VERSION ""

NS_ :

BS_:

BU_: VT OPC
VAL_TABLE_ FMI 21 "Data Drifted Low" 20 "Data Drifted High" 31 "Not available" 19 "Received network data in error" 18 "Below normal (moderately severe)" 17 "Below normal (least severe)" 16 "Above normal (moderately severe)" 15 "Above normal (least severe)" 14 "Special intstructions" 13 "Out of calibration" 12 "Bad intelligent device" 11 "Root cause not known" 10 "Abnormal rate of change" 9 "Abnormal update rate" 8 "Abnormal frequency" 7 "Mechanical system not responding" 6 "Current above normal" 5 "Current below normal" 4 "Voltage below normal" 3 "Voltage above normal" 2 "Data erratic" 1 "Below normal (most severe)" 0 "Above normal (most severe)" ;

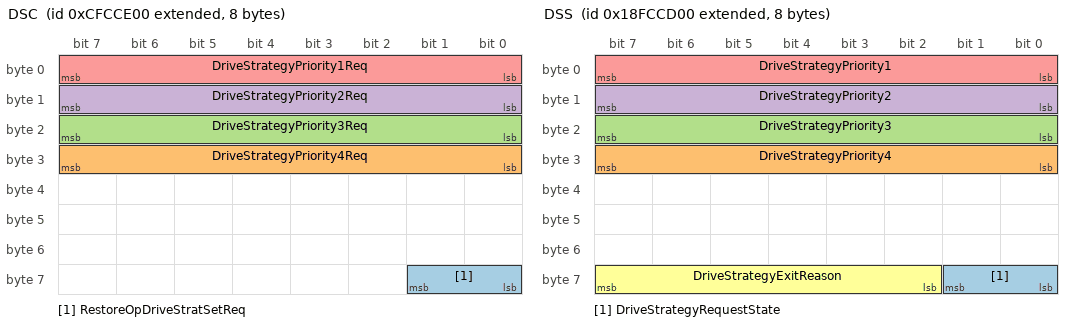
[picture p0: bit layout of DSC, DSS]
BO_ 2365378048 DSC: 8 Vector__XXX
 SG_ RestoreOpDriveStratSetReq : 56|2@1+ (1,0) [0|3] "" Vector__XXX
 SG_ DriveStrategyPriority4Req : 24|8@1+ (1,0) [0|255] "" Vector__XXX
 SG_ DriveStrategyPriority3Req : 16|8@1+ (1,0) [0|255] "" Vector__XXX
 SG_ DriveStrategyPriority2Req : 8|8@1+ (1,0) [0|255] "" Vector__XXX
 SG_ DriveStrategyPriority1Req : 0|8@1+ (1,0) [0|255] "" Vector__XXX

BO_ 2566704384 DSS: 8 Vector__XXX
 SG_ DriveStrategyRequestState : 56|2@1+ (1,0) [0|3] "" Vector__XXX
 SG_ DriveStrategyPriority4 : 24|8@1+ (1,0) [0|255] "" Vector__XXX
 SG_ DriveStrategyPriority3 : 16|8@1+ (1,0) [0|255] "" Vector__XXX
 SG_ DriveStrategyPriority2 : 8|8@1+ (1,0) [0|255] "" Vector__XXX
 SG_ DriveStrategyPriority1 : 0|8@1+ (1,0) [0|255] "" Vector__XXX
 SG_ DriveStrategyExitReason : 58|6@1+ (1,0) [0|63] "" Vector__XXX

BO_ 2566843646 VI: 8 Vector__XXX
 SG_ VehicleIdentificationNumber : 0|8@1+ (1,0) [0|255] "per byte" Vector__XXX

BO_ 2559835902 NM: 8 Vector__XXX
 SG_ NameChecksum m0 : 0|8@1+ (1,0) [0|0] "" Vector__XXX
 SG_ ErrorCode m4 : 0|8@1+ (1,0) [0|0] "" Vector__XXX
 SG_ CommandArbitraryAddressCapable m0 : 63|1@1+ (1,0) [0|1] "" Vector__XXX
 SG_ CommandVehicleSystemInstance m0 : 56|4@1+ (1,0) [0|15] "" Vector__XXX
 SG_ CommandIndustryGroup m0 : 60|3@1+ (1,0) [0|7] "" Vector__XXX
 SG_ CommandVehicleSystem m0 : 49|7@1+ (1,0) [0|127] "" Vector__XXX
 SG_ CommandFunction m0 : 40|8@1+ (1,0) [0|255] "" Vector__XXX
 SG_ CommandFunctionInstance m0 : 35|5@1+ (1,0) [0|31] "" Vector__XXX
 SG_ CommandECUInstance m0 : 32|3@1+ (1,0) [0|7] "" Vector__XXX
 SG_ CommandManufacturerCode m0 : 21|11@1+ (1,0) [0|2047] "" Vector__XXX
 SG_ NMControlModeIndicator M : 16|4@1+ (1,0) [0|15] "" Vector__XXX
 SG_ ArbitraryAddressCapableQualifier m0 : 15|1@1+ (1,0) [0|1] "" Vector__XXX
 SG_ IndustryGroupQualifierFlag m0 : 14|1@1+ (1,0) [0|1] "" Vector__XXX
 SG_ VehicleSystemInstanceQualifierFl m0 : 13|1@1+ (1,0) [0|1] "" Vector__XXX
 SG_ VehicleSystemQualifierFlag m0 : 12|1@1+ (1,0) [0|1] "" Vector__XXX
 SG_ FunctionQualifierFlag m0 : 11|1@1+ (1,0) [0|1] "" Vector__XXX
 SG_ FunctionInstanceQualifierFlag m0 : 10|1@1+ (1,0) [0|1] "" Vector__XXX
 SG_ ECUInstanceQualifierFlag m0 : 9|1@1+ (1,0) [0|1] "" Vector__XXX
 SG_ ManufacturerCodeQualifierFlag m0 : 8|1@1+ (1,0) [0|1] "" Vector__XXX

BO_ 2358116094 SCCCM: 8 Vector__XXX
 SG_ MessageCode M : 0|8@1+ (1,0) [0|255] "" Vector__XXX
 SG_ DeleteCommandType m5 : 8|8@1+ (1,0) [0|1] "" Vector__XXX
 SG_ AddressSCCWSM m4 : 8|8@1+ (1,0) [0|253] "" Vector__XXX
 SG_ MemoryRequired m145 : 8|32@1+ (1,0) [0|4294967295] "bytes" Vector__XXX
 SG_ FunctionID m50 : 8|8@1+ (1,0) [0|255] "" Vector__XXX
 SG_ SCCState m150 : 8|8@1+ (1,0) [0|2] "" Vector__XXX
 SG_ RecordedFunctionID m52 : 8|8@1+ (1,0) [0|255] "" Vector__XXX
 SG_ NumberOfFaultyFunctions m53M : 8|8@1+ (1,0) [0|255] "" Vector__XXX
 SG_ SequenceNumber m150 : 16|8@1+ (1,0) [0|255] "" Vector__XXX
 SG_ StateID m50 : 16|6@1+ (1,0) [0|63] "" Vector__XXX
 SG_ IDOfFaultyClientFunction1 m1 : 16|8@1+ (1,0) [0|255] "" Vector__XXX
 SG_ NewStateID m52 : 16|6@1+ (1,0) [0|63] "" Vector__XXX
 SG_ NewFunctionExecutionState m52 : 22|2@1+ (1,0) [0|3] "" Vector__XXX
 SG_ FunctionExecutionState m50M : 22|2@1+ (1,0) [0|3] "" Vector__XXX
 SG_ SequenceState m150 : 24|8@1+ (1,0) [0|255] "" Vector__XXX
 SG_ ClientAbortError m49 : 24|8@1+ (1,0) [0|255] "" Vector__XXX
 SG_ ClientFunctionErrorStatuts1 m1 : 24|4@1+ (1,0) [0|15] "" Vector__XXX
 SG_ ClientExecutionError m52 : 24|8@1+ (1,0) [0|255] "" Vector__XXX
 SG_ TAN m50 : 24|8@1+ (1,0) [0|255] "" Vector__XXX
 SG_ OperatorConfirmationRequired1 m1 : 31|1@1+ (1,0) [0|1] "" Vector__XXX
 SG_ ClientFunctonErrorState m150 : 32|8@1+ (1,0) [0|255] "" Vector__XXX
 SG_ IDOfFaultyClientFunction2 m2 : 32|8@1+ (1,0) [0|255] "" Vector__XXX
 SG_ FunctionValue m0 : 32|32@1+ (1,0) [0|4294967295] "" Vector__XXX
 SG_ ReceivedTAN m52 : 32|8@1+ (1,0) [0|255] "" Vector__XXX
 SG_ ClientFunctionErrorStatuts2 m2 : 40|4@1+ (1,0) [0|15] "" Vector__XXX
 SG_ OperatorConfirmationRequired2 m2 : 47|1@1+ (1,0) [0|1] "" Vector__XXX
 SG_ IDOfFaultyClientFunction3 m3 : 48|8@1+ (1,0) [0|255] "" Vector__XXX
 SG_ ClientFunctionErrorStatuts3 m3 : 56|4@1+ (1,0) [0|15] "" Vector__XXX
 SG_ OperatorConfirmationRequired3 m3 : 63|1@1+ (1,0) [0|1] "" Vector__XXX

BO_ 2358181630 SCMCC: 8 Vector__XXX
 SG_ MessageCode M : 0|8@1+ (1,0) [0|255] "" Vector__XXX
 SG_ LoadResponseError m7 : 8|8@1+ (1,0) [0|255] "" Vector__XXX
 SG_ StoreCommandError m6 : 8|8@1+ (1,0) [0|255] "" Vector__XXX
 SG_ DeleteCommandResponseError m5 : 8|8@1+ (1,0) [0|255] "" Vector__XXX
 SG_ CommandedSCCState m48 : 8|8@1+ (1,0) [0|1] "" Vector__XXX
 SG_ SCVersion m144 : 8|8@1+ (1,0) [0|255] "" Vector__XXX
 SG_ FunctionID m50 : 8|8@1+ (1,0) [0|255] "" Vector__XXX
 SG_ SCMState m149 : 8|8@1+ (1,0) [0|2] "" Vector__XXX
 SG_ ActivationResponseError m4 : 8|8@1+ (1,0) [0|255] "" Vector__XXX
 SG_ TransferResponseError m3 : 8|8@1+ (1,0) [0|255] "" Vector__XXX
 SG_ ConfigLabelResponseError m2M : 8|8@1+ (1,0) [0|255] "" Vector__XXX
 SG_ VersionResponseError m1M : 8|8@1+ (1,0) [0|255] "" Vector__XXX
 SG_ MemoryStatus m145 : 8|8@1+ (1,0) [0|1] "" Vector__XXX
 SG_ RecordedFunctionID m51 : 8|8@1+ (1,0) [0|255] "" Vector__XXX
 SG_ ObjectIdOfFirstFaultyObject m4 : 16|16@1+ (1,0) [0|65535] "" Vector__XXX
 SG_ SequenceNumber m149 : 16|8@1+ (1,0) [0|255] "" Vector__XXX
 SG_ RecordedStateID m51 : 16|6@1+ (1,0) [0|63] "" Vector__XXX
 SG_ GraphicsWidth m144 : 16|8@1+ (1,0) [32|255] "" Vector__XXX
 SG_ ActualVersionLabel m0 : 16|8@1+ (1,0) [0|255] "" Vector__XXX
 SG_ ActualConfigurationLabel m0 : 16|8@1+ (1,0) [0|255] "" Vector__XXX
 SG_ StateID m50 : 16|6@1+ (1,0) [0|63] "" Vector__XXX
 SG_ FunctionExecutionStateAck m52 : 22|2@1+ (1,0) [0|3] "" Vector__XXX
 SG_ FunctionExecutionState m50 : 22|2@1+ (1,0) [0|3] "" Vector__XXX
 SG_ GraphicsHeight m144 : 24|8@1+ (1,0) [32|255] "" Vector__XXX
 SG_ ReasonIndicator m48 : 24|8@1+ (1,0) [0|255] "" Vector__XXX
 SG_ SequenceState m149 : 24|8@1+ (1,0) [0|255] "" Vector__XXX
 SG_ TAN m51 : 24|8@1+ (1,0) [0|255] "" Vector__XXX
 SG_ ExecutionIndicationResponseError m50 : 24|8@1+ (1,0) [0|255] "" Vector__XXX
 SG_ BusyFlagMemoryAccess m149 : 32|1@1+ (1,0) [0|1] "" Vector__XXX
 SG_ RecordedFunctionValue m51 : 32|32@1+ (1,0) [0|4294967295] "" Vector__XXX
 SG_ ReceivedTAN m50 : 32|8@1+ (1,0) [0|255] "" Vector__XXX
 SG_ BusyFlagParsing m149 : 33|1@1+ (1,0) [0|1] "" Vector__XXX
 SG_ MaxDesignatorStringLength m144 : 32|16@1+ (1,0) [0|65535] "" Vector__XXX

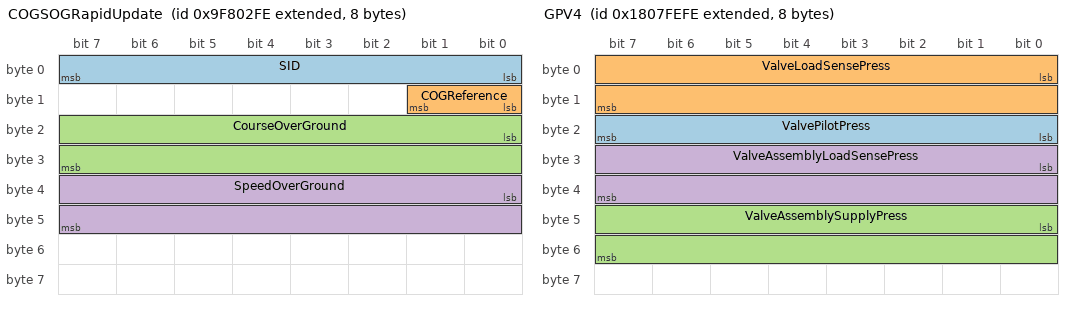
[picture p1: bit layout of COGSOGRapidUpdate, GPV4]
BO_ 2314732286 COGSOGRapidUpdate: 8 Vector__XXX
 SG_ SID : 0|8@1+ (1,0) [0|252] "" Vector__XXX
 SG_ COGReference : 8|2@1+ (1,0) [0|3] "" Vector__XXX
 SG_ CourseOverGround : 16|16@1+ (0.0001,0) [0|6.28318] "rad" Vector__XXX
 SG_ SpeedOverGround : 32|16@1+ (0.01,0) [0|655.32] "m/s" Vector__XXX

BO_ 2365391360 AISO: 8 Vector__XXX
 SG_ StopAllImplementOperations : 56|2@1- (1,0) [0|3] "" Vector__XXX

BO_ 2365391616 IOS: 8 Vector__XXX
 SG_ ImplementOperatingStateCmd : 56|2@1+ (1,0) [0|3] "" Vector__XXX

BO_ 2566835454 DM3: 0 Vector__XXX

BO_ 2364547838 MSS: 9 Vector__XXX
 SG_ MachineSelectedSpeed : 0|16@1+ (0.001,0) [0|65.535] "m/s" Vector__XXX
 SG_ MachineSelectedDistance : 16|32@1+ (0.001,0) [0|4211081.215] "m" Vector__XXX
 SG_ MachineSelectedDirection : 56|2@1+ (1,0) [0|3] "" Vector__XXX
 SG_ MachineSelectedSpeedSource : 58|3@1+ (1,0) [0|7] "" Vector__XXX
 SG_ MachineSelectedSpeedLimitStatus : 61|3@1+ (1,0) [0|7] "" Vector__XXX

BO_ 2550660862 GPV4: 8 Vector__XXX
 SG_ ValvePilotPress : 16|8@1+ (16,0) [0|4000] "kPa" Vector__XXX
 SG_ ValveLoadSensePress : 0|16@1+ (5,0) [0|321275] "kPa" Vector__XXX
 SG_ ValveAssemblySupplyPress : 40|16@1+ (5,0) [0|321275] "kPa" Vector__XXX
 SG_ ValveAssemblyLoadSensePress : 24|16@1+ (5,0) [0|321275] "kPa" Vector__XXX

BO_ 2566730494 DP: 8 Vector__XXX
 SG_ DiagnosticOptions m23 : 40|8@1+ (1,0) [0|255] "" Vector__XXX
 SG_ StopAllImplementOperationsOption m21 : 40|8@1+ (1,0) [0|0] "" Vector__XXX
 SG_ SequenceControlFuncOptions m19 : 40|8@1+ (1,0) [0|255] "" Vector__XXX
 SG_ AdvanceTECU_MotionInitiationOpti m15 : 46|1@1+ (1,0) [0|1] "" Vector__XXX
 SG_ AdvanceTECU_PowertrainOption m15 : 45|1@1+ (1,0) [0|1] "" Vector__XXX
 SG_ AdvanceTECU_GuidanceOption m15 : 44|1@1+ (1,0) [0|1] "" Vector__XXX
 SG_ AdvanceTECU_FrontHitchOption m15 : 43|1@1+ (1,0) [0|1] "" Vector__XXX
 SG_ AdvanceTECU_NavigationOption m15 : 42|1@1+ (1,0) [0|1] "" Vector__XXX
 SG_ AdvanceTECU_FullLightingMsgSet m15 : 41|1@1+ (1,0) [0|1] "" Vector__XXX
 SG_ AdvanceTECU_Class3NoOptions m15 : 40|1@1+ (1,0) [0|1] "" Vector__XXX
 SG_ BasicTECU_GuidanceOption m13 : 45|1@1+ (1,0) [0|1] "" Vector__XXX
 SG_ BasicTECU_FrontHitchOption m13 : 44|1@1+ (1,0) [0|1] "" Vector__XXX
 SG_ BasicTECU_NavigationOption m13 : 43|1@1+ (1,0) [0|1] "" Vector__XXX
 SG_ BasicTECU_ClassRequiredLighting m13 : 42|1@1+ (1,0) [0|1] "" Vector__XXX
 SG_ BasicTECU_Class2NoOptions m13 : 41|1@1+ (1,0) [0|1] "" Vector__XXX
 SG_ BasicTECU_Class1NoOptions m13 : 40|1@1+ (1,0) [0|1] "" Vector__XXX
 SG_ TCSectionNumberOfSections m11 : 48|8@1+ (1,0) [0|250] "" Vector__XXX
 SG_ TCSectionNumberOfBooms m11 : 40|8@1+ (1,0) [0|250] "" Vector__XXX
 SG_ TCGeoFuncOptions m9 : 48|8@1+ (1,0) [0|0] "" Vector__XXX
 SG_ TCGeoSupportedChannels m9 : 40|8@1+ (1,0) [0|250] "" Vector__XXX
 SG_ TCBasicFuncOptions m7 : 40|8@1+ (1,0) [0|255] "" Vector__XXX
 SG_ AuxType2_SupportFunc14 m5 : 54|1@1+ (1,0) [0|1] "" Vector__XXX
 SG_ AuxType2_SupportFunc13 m5 : 53|1@1+ (1,0) [0|1] "" Vector__XXX
 SG_ AuxType2_SupportFunc12 m5 : 52|1@1+ (1,0) [0|1] "" Vector__XXX
 SG_ AuxType2_SupportFunc11 m5 : 51|1@1+ (1,0) [0|1] "" Vector__XXX
 SG_ AuxType2_SupportFunc10 m5 : 50|1@1+ (1,0) [0|1] "" Vector__XXX
 SG_ AuxType2_SupportFunc09 m5 : 49|1@1+ (1,0) [0|1] "" Vector__XXX
 SG_ AuxType2_SupportFunc08 m5 : 48|1@1+ (1,0) [0|1] "" Vector__XXX
 SG_ AuxType2_SupportFunc07 m5 : 47|1@1+ (1,0) [0|1] "" Vector__XXX
 SG_ AuxType2_SupportFunc06 m5 : 46|1@1+ (1,0) [0|1] "" Vector__XXX
 SG_ AuxType2_SupportFunc05 m5 : 45|1@1+ (1,0) [0|1] "" Vector__XXX
 SG_ AuxType2_SupportFunc04 m5 : 44|1@1+ (1,0) [0|1] "" Vector__XXX
 SG_ AuxType2_SupportFunc03 m5 : 43|1@1+ (1,0) [0|1] "" Vector__XXX
 SG_ AuxType2_SupportFunc02 m5 : 42|1@1+ (1,0) [0|1] "" Vector__XXX
 SG_ AuxType2_SupportFunc01 m5 : 41|1@1+ (1,0) [0|1] "" Vector__XXX
 SG_ AuxType2_SupportFunc00 m5 : 40|1@1+ (1,0) [0|1] "" Vector__XXX
 SG_ AuxType1_SupportFunc2 m3 : 42|1@1+ (1,0) [0|1] "" Vector__XXX
 SG_ AuxType1_SupportFunc1 m3 : 41|1@1+ (1,0) [0|1] "" Vector__XXX
 SG_ AuxType1_SupportFunc0 m3 : 40|1@1+ (1,0) [0|1] "" Vector__XXX
 SG_ VTFuncOptions m1 : 40|8@1+ (1,0) [0|250] "" Vector__XXX
 SG_ NumOfFirstListedFuncOptionBytes : 32|8@1+ (1,0) [0|2] "" Vector__XXX
 SG_ FirstListedFuncGen : 24|8@1+ (1,0) [0|255] "" Vector__XXX
 SG_ FirstListedFuncCharacteristic M : 16|8@1+ (1,0) [0|255] "" Vector__XXX
 SG_ NumOfReportedFuncCharacteristics : 8|8@1+ (1,0) [0|255] "" Vector__XXX
 SG_ J1939_73 : 0|1@1+ (1,0) [0|1] "" Vector__XXX
 SG_ ISO14230 : 1|1@1+ (1,0) [0|1] "" Vector__XXX
 SG_ ISO15765_3 : 2|1@1+ (1,0) [0|1] "" Vector__XXX
 SG_ ISO11783Level2 : 3|1@1+ (1,0) [0|1] "" Vector__XXX

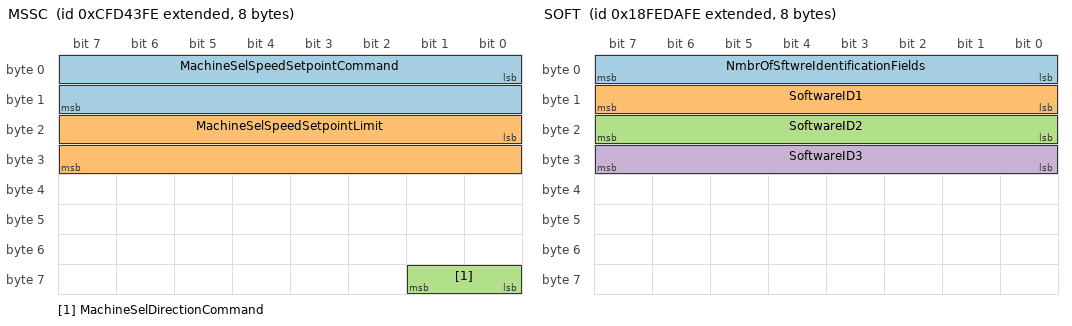
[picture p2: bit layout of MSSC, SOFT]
BO_ 2365408254 MSSC: 8 Vector__XXX
 SG_ MachineSelSpeedSetpointCommand : 0|16@1+ (0.001,0) [0|64255] "m/s" Vector__XXX
 SG_ MachineSelSpeedSetpointLimit : 16|16@1+ (0.001,0) [0|64255] "m/s" Vector__XXX
 SG_ MachineSelDirectionCommand : 56|2@1+ (1,0) [0|3] "" Vector__XXX

BO_ 2566734590 ICC: 8 Vector__XXX
 SG_ CertTypeTCSectionControlWSMember : 41|1@1+ (1,0) [0|1] "" Vector__XXX
 SG_ CertTypeTCSectionControl : 42|1@1+ (1,0) [0|1] "" Vector__XXX
 SG_ CertTypeSeqControlMaster : 44|1@1+ (1,0) [0|1] "" Vector__XXX
 SG_ CertTypeSecControlClient : 43|1@1+ (1,0) [0|1] "" Vector__XXX
 SG_ CertTypeFileClient : 45|1@1+ (1,0) [0|1] "" Vector__XXX
 SG_ CertTypeDataLoggerWSMember : 46|1@1+ (1,0) [0|1] "" Vector__XXX
 SG_ CertTypeDataLoggerWSMaster : 47|1@1+ (1,0) [0|1] "" Vector__XXX
 SG_ CertTypeDataLogger : 32|1@1+ (1,0) [0|1] "" Vector__XXX
 SG_ CertTypeAuxControlInUnit : 34|1@1+ (1,0) [0|1] "" Vector__XXX
 SG_ CertTypeAuxControlFunc : 33|1@1+ (1,0) [0|1] "" Vector__XXX
 SG_ CertificationYear : 0|6@1+ (1,2000) [2000|2061] "year" Vector__XXX
 SG_ CertificateRevision : 6|2@1+ (1,0) [0|3] "" Vector__XXX
 SG_ CertificateLaboratoryType : 9|2@1+ (1,0) [0|3] "" Vector__XXX
 SG_ CertificationLaboratoryID : 13|11@1+ (1,0) [0|2047] "" Vector__XXX
 SG_ CertTypeVTWorkingSetMember : 24|1@1+ (1,0) [0|1] "" Vector__XXX
 SG_ CertTypeVTWorkingSetMaster : 25|1@1+ (1,0) [0|1] "" Vector__XXX
 SG_ CertTypeVirtualTerminal : 26|1@1+ (1,0) [0|1] "" Vector__XXX
 SG_ CertTypeClass3ECU : 27|1@1+ (1,0) [0|1] "" Vector__XXX
 SG_ CertTypeTECUClass3 : 28|1@1+ (1,0) [0|1] "" Vector__XXX
 SG_ CertTypeTECUClass2 : 29|1@1+ (1,0) [0|1] "" Vector__XXX
 SG_ CertTypeTECUClass1 : 30|1@1+ (1,0) [0|1] "" Vector__XXX
 SG_ CertTypeMinimumECU : 31|1@1+ (1,0) [0|1] "" Vector__XXX
 SG_ CertTypeGPSReceiver : 35|1@1+ (1,0) [0|1] "" Vector__XXX
 SG_ CertTypeFileServer : 36|1@1+ (1,0) [0|1] "" Vector__XXX
 SG_ CertTypeTCWorkingSetMember : 37|1@1+ (1,0) [0|1] "" Vector__XXX
 SG_ CertTypeTCWorkingSetMaster : 38|1@1+ (1,0) [0|1] "" Vector__XXX
 SG_ CertTypeTaskController : 39|1@1+ (1,0) [0|1] "" Vector__XXX
 SG_ CertificationReferenceNumber : 48|16@1+ (1,0) [0|65535] "" Vector__XXX

BO_ 2566835198 DM2: 22 Vector__XXX
 SG_ DTC1 : 16|32@1+ (1,0) [0|4294967295] "" Vector__XXX
 SG_ DTC2 : 48|32@1+ (1,0) [0|4294967295] "" Vector__XXX
 SG_ DTC3 : 80|32@1+ (1,0) [0|4294967295] "" Vector__XXX
 SG_ DTC4 : 112|32@1+ (1,0) [0|4294967295] "" Vector__XXX
 SG_ DTC5 : 144|32@1+ (1,0) [0|4294967295] "" Vector__XXX

BO_ 2566834942 DM1: 22 Vector__XXX
 SG_ DTC1 : 16|32@1+ (1,0) [0|4294967295] "" Vector__XXX
 SG_ DTC2 : 48|32@1+ (1,0) [0|4294967295] "" Vector__XXX
 SG_ DTC3 : 80|32@1+ (1,0) [0|4294967295] "" Vector__XXX
 SG_ DTC4 : 112|32@1+ (1,0) [0|4294967295] "" Vector__XXX
 SG_ DTC5 : 144|32@1+ (1,0) [0|4294967295] "" Vector__XXX

BO_ 2566839038 SOFT: 8 Vector__XXX
 SG_ NmbrOfSftwreIdentificationFields : 0|8@1+ (1,0) [0|250] "steps" Vector__XXX
 SG_ SoftwareID1 : 8|8@1+ (1,0) [0|255] "" Vector__XXX
 SG_ SoftwareID2 : 16|8@1+ (1,0) [0|255] "" Vector__XXX
 SG_ SoftwareID3 : 24|8@1+ (1,0) [0|255] "" Vector__XXX

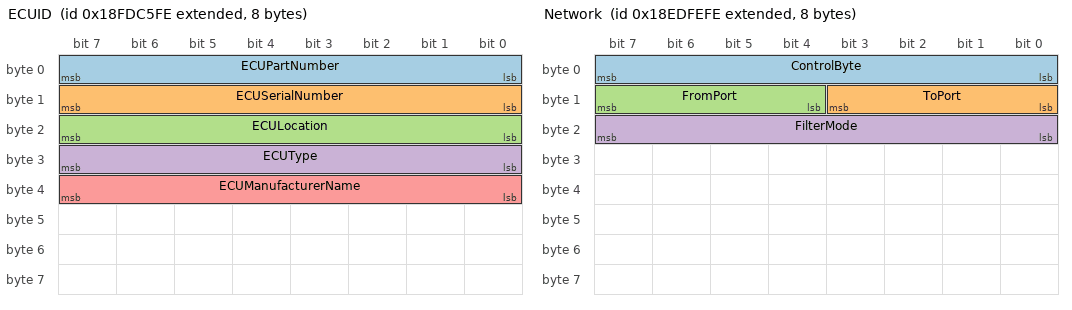
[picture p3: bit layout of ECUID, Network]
BO_ 2566768126 ECUID: 8 Vector__XXX
 SG_ ECUPartNumber : 0|8@1+ (1,0) [0|255] "" Vector__XXX
 SG_ ECUSerialNumber : 8|8@1+ (1,0) [0|255] "" Vector__XXX
 SG_ ECULocation : 16|8@1+ (1,0) [0|255] "" Vector__XXX
 SG_ ECUType : 24|8@1+ (1,0) [0|255] "" Vector__XXX
 SG_ ECUManufacturerName : 32|8@1+ (1,0) [0|255] "" Vector__XXX

BO_ 2566838526 CA: 9 Vector__XXX
 SG_ IdentityNumber : 0|21@1+ (1,0) [0|2097152] "" Vector__XXX
 SG_ ManufacturerCode : 21|11@1+ (1,0) [0|2047] "" Vector__XXX
 SG_ ECUInstance : 32|3@1+ (1,0) [0|7] "" Vector__XXX
 SG_ FunctionInstance : 35|5@1+ (1,0) [0|31] "" Vector__XXX
 SG_ Function : 40|8@1+ (1,0) [0|255] "" Vector__XXX
 SG_ VehicleSystem m0 : 49|7@1+ (1,0) [0|127] "" Vector__XXX
 SG_ VehicleSystem5 m5 : 49|7@1+ (1,0) [0|127] "" Vector__XXX
 SG_ VehicleSystem4 m4 : 49|7@1+ (1,0) [0|127] "" Vector__XXX
 SG_ VehicleSystem3 m3 : 49|7@1+ (1,0) [0|127] "" Vector__XXX
 SG_ VehicleSystem2 m2 : 49|7@1+ (1,0) [0|127] "" Vector__XXX
 SG_ VehicleSystem1 m1 : 49|7@1+ (1,0) [0|127] "" Vector__XXX
 SG_ VehicleSystemInstance : 56|4@1+ (1,0) [0|15] "" Vector__XXX
 SG_ IndustryGroup M : 60|3@1+ (1,0) [0|7] "" Vector__XXX
 SG_ ArbitraryAddressCapable : 63|1@1+ (1,0) [0|1] "" Vector__XXX
 SG_ AddressAssignment : 64|8@1+ (1,0) [0|255] "" Vector__XXX

BO_ 2565799678 ACL: 8 OPC
 SG_ IdentityNumber : 0|21@1+ (1,0) [0|2097152] "" Vector__XXX
 SG_ ManufacturerCode : 21|11@1+ (1,0) [0|2047] "" Vector__XXX
 SG_ ECUInstance : 32|3@1+ (1,0) [0|7] "" Vector__XXX
 SG_ FunctionInstance : 35|5@1+ (1,0) [0|31] "" Vector__XXX
 SG_ Function : 40|8@1+ (1,0) [0|255] "" Vector__XXX
 SG_ VehicleSystem1 m1 : 49|7@1+ (1,0) [0|127] "" Vector__XXX
 SG_ VehicleSystem2 m2 : 49|7@1+ (1,0) [0|127] "" Vector__XXX
 SG_ VehicleSystem3 m3 : 49|7@1+ (1,0) [0|127] "" Vector__XXX
 SG_ VehicleSystem4 m4 : 49|7@1+ (1,0) [0|127] "" Vector__XXX
 SG_ VehicleSystem5 m5 : 49|7@1+ (1,0) [0|127] "" Vector__XXX
 SG_ VehicleSystem m0 : 49|7@1+ (1,0) [0|127] "" Vector__XXX
 SG_ VehicleSystemInstance : 56|4@1+ (1,0) [0|15] "" Vector__XXX
 SG_ IndustryGroup M : 60|3@1+ (1,0) [0|7] "" Vector__XXX
 SG_ ArbitraryAddressCapable : 63|1@1+ (1,0) [0|1] "" Vector__XXX
 SG_ IdentityNumber : 0|21@1+ (1,0) [0|2097152] "" Vector__XXX
 SG_ ManufacturerCode : 21|11@1+ (1,0) [0|2047] "" Vector__XXX
 SG_ ECUInstance : 32|3@1+ (1,0) [0|7] "" Vector__XXX
 SG_ FunctionInstance : 35|5@1+ (1,0) [0|31] "" Vector__XXX
 SG_ Function : 40|8@1+ (1,0) [0|255] "" Vector__XXX
 SG_ VehicleSystem1 m1 : 49|7@1+ (1,0) [0|127] "" Vector__XXX
 SG_ VehicleSystem2 m2 : 49|7@1+ (1,0) [0|127] "" Vector__XXX
 SG_ VehicleSystem3 m3 : 49|7@1+ (1,0) [0|127] "" Vector__XXX
 SG_ VehicleSystem4 m4 : 49|7@1+ (1,0) [0|127] "" Vector__XXX
 SG_ VehicleSystem5 m5 : 49|7@1+ (1,0) [0|127] "" Vector__XXX
 SG_ VehicleSystem m0 : 49|7@1+ (1,0) [0|127] "" Vector__XXX
 SG_ VehicleSystemInstance : 56|4@1+ (1,0) [0|15] "" Vector__XXX
 SG_ IndustryGroup M : 60|3@1+ (1,0) [0|7] "" Vector__XXX
 SG_ ArbitraryAddressCapable : 63|1@1+ (1,0) [0|1] "" Vector__XXX

BO_ 2565734142 Network: 8 Vector__XXX
 SG_ ControlByte : 0|8@1+ (1,0) [0|255] "" Vector__XXX
 SG_ ToPort : 8|4@1+ (1,0) [0|15] "" Vector__XXX
 SG_ FromPort : 12|4@1+ (1,0) [0|15] "" Vector__XXX
 SG_ FilterMode : 16|8@1+ (1,0) [0|255] "" Vector__XXX

CM_ BU_ VT "Virtual Terminal";
CM_ BU_ OPC "Object Pool Checker";
CM_ SG_ 2365378048 RestoreOpDriveStratSetReq "This parameter requests the drive strategy subsystem to restore the settings for drive strategy to the state 
before automation was ended. ";
CM_ SG_ 2365378048 DriveStrategyPriority4Req "This parameter used to request an alteration to the tractor drive strategy priority structure, which determines 
the  balance  between  fuel  economy/consumption  and  the  torque  reserve  of  the  engine - the lowest priority request.  ";
CM_ SG_ 2365378048 DriveStrategyPriority3Req "This parameter used to request an alteration to the tractor drive strategy priority structure, which determines 
the  balance  between  fuel  economy/consumption  and  the  torque  reserve  of  the  engine - the third to highest priority request.";
CM_ SG_ 2365378048 DriveStrategyPriority2Req "This parameter used to request an alteration to the tractor drive strategy priority structure, which determines 
the  balance  between  fuel  economy/consumption  and  the  torque  reserve  of  the  engine - the second to highest priority request.";
CM_ SG_ 2365378048 DriveStrategyPriority1Req "This parameter used to request an alteration to the tractor drive strategy priority structure, which determines 
the  balance  between  fuel  economy/consumption  and  the  torque  reserve  of  the  engine - the highest priority request.";
CM_ BO_ 2566704384 "Message sent from the tractor to the implement to indicate the current status, of the drive strategy priority 
structure, which indicates the priority of the multiple powertrain functions. ";
CM_ SG_ 2566704384 DriveStrategyRequestState "This  parmeter  reports  the  tractor's  state  associated  with  Drive  Strategy  requests  that  are 
transient/temporary/one-shot.";
CM_ SG_ 2566704384 DriveStrategyPriority4 "This parameter indicates the current Tractor drive strategy priority structure, which determines the balance 
between  fuel  economy/consumption  and  the  torque  reserve  of  the  engine.  This  parameter  indicates  the 
lowest priority. ";
CM_ SG_ 2566704384 DriveStrategyPriority3 "This parameter indicates the current Tractor drive strategy priority structure, which determines the balance 
between  fuel  economy/consumption  and  the  torque  reserve  of  the  engine.  This  parameter  indicates 
 the third to highest priority. ";
CM_ SG_ 2566704384 DriveStrategyPriority2 "This parameter indicates the current Tractor drive strategy priority structure, which determines the balance 
between  fuel  economy/consumption  and  the  torque  reserve  of  the  engine.  This  parameter  indicates 
 the second to highest priority. ";
CM_ SG_ 2566704384 DriveStrategyPriority1 "This parameter indicates the current Tractor drive strategy priority structure, which determines the balance 
between  fuel  economy/consumption  and  the  torque  reserve  of  the  engine.  This  parameter  indicates  the 
highest priority. ";
CM_ SG_ 2566704384 DriveStrategyExitReason "Parameter used to indicate why the drive strategy subsystem cannot currently accept remote commands or 
has most recently stopped accepting remote commands.";
CM_ BO_ 2566843646 "Byte: 1-n Vehicle Identification Number 
Delimiter (ASCII “*”)";
CM_ SG_ 2566843646 VehicleIdentificationNumber "Vehicle Identification Number (VIN) as assigned by the vehicle manufacturer.";
CM_ BO_ 2358116094 "Sequence Control Client to Sequence Control Master";
CM_ SG_ 2358116094 AddressSCCWSM "Source address of SCC's working set master";
CM_ SG_ 2358116094 MemoryRequired "Volatile memory required, number of bytes of the SCD to upload";
CM_ SG_ 2358116094 ClientAbortError "Error code of a SCClientAbort";
CM_ BO_ 2358181630 "Sequence Control Master to Sequence Control Client";
CM_ SG_ 2358181630 MessageCode "Message code of the SCMCC message";
CM_ SG_ 2358181630 SCVersion "Version of supported SC standard";
CM_ SG_ 2358181630 SCMState "State of sending SCM";
CM_ SG_ 2358181630 TransferResponseError "Error code of the SCDTransferResponse";
CM_ SG_ 2358181630 ConfigLabelResponseError "Error code of SCDConfigurationLabelResponse";
CM_ SG_ 2358181630 VersionResponseError "Error code of the SCDVersionResponse";
CM_ SG_ 2358181630 MemoryStatus "Status of the SCMasterMemoryResponse";
CM_ SG_ 2358181630 ObjectIdOfFirstFaultyObject "Object ID of first faulty object";
CM_ SG_ 2358181630 GraphicsWidth "Number of pixels on the X axis for graphics objects";
CM_ SG_ 2358181630 GraphicsHeight "Number of pixels on the Y axis for graphics objects";
CM_ SG_ 2358181630 MaxDesignatorStringLength "Maximum number of displayed characters for designator strings";
CM_ BO_ 2314732286 "This PGN is a single frame PGN that provides Course Over Ground(COG)and Speed Over Ground(SOG).

Being a single frame Msg,as opposed to other PGNs that include COG and SOG and are defined as multi-packet,this PGN lends itself to being transmitted more f";
CM_ SG_ 2314732286 SID "An upward counting number used to tie related information together between different PGNs.For example,SID would be used to tie together COG,SOG and RAIM values to a given Pos.255=no valid Pos fix to tie it to.Range 0 to 250 for valid Pos fixes.";
CM_ SG_ 2314732286 COGReference "0 = True, 
1 = Magnetic, 
2 = Error, 
3 = Null";
CM_ SG_ 2314732286 CourseOverGround "The direction of the path over ground actually followed by a vessel.";
CM_ BO_ 2365391360 " All implements stop operations switch state";
CM_ BO_ 2365391616 "Implement operating state command";
CM_ BO_ 2566835454 "Diagnostic data clear/reset of previously active DTCs.";
CM_ BO_ 2364547838 "Machine selected speed";
CM_ SG_ 2364547838 MachineSelectedSpeed "Machine selected Speed";
CM_ SG_ 2364547838 MachineSelectedDistance "Machine selected Distance";
CM_ SG_ 2364547838 MachineSelectedDirection "Machine selected direction";
CM_ SG_ 2364547838 MachineSelectedSpeedSource "Machine selected speed source";
CM_ SG_ 2364547838 MachineSelectedSpeedLimitStatus "Machine selected speed limit status";
CM_ BO_ 2550660862 "General purpose valve load sense pressure";
CM_ SG_ 2550660862 ValvePilotPress "Pressure of a valve's pilot supply port.";
CM_ SG_ 2550660862 ValveLoadSensePress "The maximum of the currently measured pressures of a valve's work port A and work port B.";
CM_ SG_ 2550660862 ValveAssemblySupplyPress "Pressure of the hydraulic supply port to a valve assembly.";
CM_ SG_ 2550660862 ValveAssemblyLoadSensePress "The maximum pressure of a valve assembly's current collective load sense pressures where a valve assembly can ...";
CM_ BO_ 2566730494 "ECU diagnostic protocol";
CM_ SG_ 2566730494 DiagnosticOptions "This  parameter  reports  which  diagnostics  functionality  options  are  supported  by  a  controller  or  external 
diagnostic tool that is connected to the ISO 11783 network. ";
CM_ SG_ 2566730494 StopAllImplementOperationsOption "This  parameter  reports  which  stop  all  implement  operations  functionality  options  are  supported  by  an 
implement working set master or a stop all implement operations input unit that is connected to the ISO 11783 
network. ";
CM_ SG_ 2566730494 SequenceControlFuncOptions "This parameter reports which sequence control (SQC) functionality options are supported by an implement 
working set master or a sequence control master that is connected to the ISO 11783 network. ";
CM_ SG_ 2566730494 TCSectionNumberOfSections "This parameter reports how many sections are required by an implement working set master or supported by 
a task controller geo that is connected to the ISO 11783 network. ";
CM_ SG_ 2566730494 TCSectionNumberOfBooms "This parameter reports how many booms are required by an implement working set master or supported by a 
task controller geo that is connected to the ISO 11783 network. ";
CM_ SG_ 2566730494 TCGeoFuncOptions "This parameter reports which task controller geo functionality options are supported by an implement working 
set master or a task controller that is connected to the ISO 11783 network. ";
CM_ SG_ 2566730494 TCGeoSupportedChannels "This  parameter  reports  the  number  of  control  channels  are  required  by  a  TC-GEO  implement  working  set 
master or supported by a TC-GEO service type task controller that is connected to the ISO 11783 network. ";
CM_ SG_ 2566730494 TCBasicFuncOptions "This  parameter  reports  which  basic  task  controller  functionality  options  are  supported  by  an  implement 
working set master or a task controller that is connected to the ISO 11783 network.";
CM_ SG_ 2566730494 VTFuncOptions "This parameter reports which VT functionality options are supported by an implement working set master or a 
VT that is connected to the ISO 11783 network. ";
CM_ SG_ 2566730494 FirstListedFuncGen "This parameter reports the generation of the first listed functionality.";
CM_ SG_ 2566730494 FirstListedFuncCharacteristic "This parameter reports which functionalities characteristics are supported by a control function connected to 
the ISO 11783 network.";
CM_ SG_ 2566730494 NumOfReportedFuncCharacteristics "Number of functionality characteristics reported in this message";
CM_ SG_ 2566730494 J1939_73 "J1939-73";
CM_ SG_ 2566730494 ISO14230 "ISO 14230 (KWP 2000 over K line)";
CM_ SG_ 2566730494 ISO15765_3 "ISO 15765-3 (UDS on CAN)";
CM_ SG_ 2566730494 ISO11783Level2 "ISO 11783 Level 2";
CM_ BO_ 2365408254 "Machine Selected Speed Command";
CM_ SG_ 2365408254 MachineSelSpeedSetpointCommand "Machine selected speed setpoint command";
CM_ SG_ 2365408254 MachineSelSpeedSetpointLimit "Machine selected speed setpoint limit";
CM_ SG_ 2365408254 MachineSelDirectionCommand "Machine selected direction command";
CM_ BO_ 2566734590 "ISOBUS compliance certification";
CM_ SG_ 2566734590 CertTypeTCSectionControlWSMember "Parameter used to indicate the type of compliance test performed. ";
CM_ SG_ 2566734590 CertTypeTCSectionControl "Parameter used to indicate the type of compliance test performed. ";
CM_ SG_ 2566734590 CertTypeSeqControlMaster "Parameter used to indicate the type of compliance test performed. ";
CM_ SG_ 2566734590 CertTypeSecControlClient "Parameter used to indicate the type of compliance test performed. ";
CM_ SG_ 2566734590 CertTypeFileClient "Parameter used to indicate the type of compliance test performed. ";
CM_ SG_ 2566734590 CertTypeDataLoggerWSMember "Parameter used to indicate the type of compliance test performed. ";
CM_ SG_ 2566734590 CertTypeDataLoggerWSMaster "Parameter used to indicate the type of compliance test performed. ";
CM_ SG_ 2566734590 CertTypeDataLogger "Parameter used to indicate the type of compliance test performed. ";
CM_ SG_ 2566734590 CertTypeAuxControlInUnit "Parameter used to indicate the type of compliance test performed.";
CM_ SG_ 2566734590 CertTypeAuxControlFunc "Parameter used to indicate the type of compliance test performed. ";
CM_ SG_ 2566734590 CertificationYear "ISOBUS compliance certification year";
CM_ SG_ 2566734590 CertificateRevision "ISOBUS compliance certificate revision";
CM_ SG_ 2566734590 CertificateLaboratoryType "ISOBUS compliance certificate laboratory type";
CM_ SG_ 2566734590 CertificationLaboratoryID "ISOBUS Compliance certification laboratory ID";
CM_ SG_ 2566734590 CertTypeVTWorkingSetMember "ISOBUS Compliance certification type - VT working set member";
CM_ SG_ 2566734590 CertTypeVTWorkingSetMaster "ISOBUS Compliance certification type - VT working set master";
CM_ SG_ 2566734590 CertTypeVirtualTerminal "ISOBUS Compliance certification type - Virtual terminal";
CM_ SG_ 2566734590 CertTypeClass3ECU "ISOBUS Compliance certification type - Class 3 ECU";
CM_ SG_ 2566734590 CertTypeTECUClass3 "ISOBUS Compliance certification type - TECU Class 3";
CM_ SG_ 2566734590 CertTypeTECUClass2 "ISOBUS Compliance certification type - TECU Class 2";
CM_ SG_ 2566734590 CertTypeTECUClass1 "ISOBUS Compliance certification type - TECU Class 1";
CM_ SG_ 2566734590 CertTypeMinimumECU "ISOBUS Compliance certification type - Minimum ECU";
CM_ SG_ 2566734590 CertTypeGPSReceiver "ISOBUS Compliance certification type - GPS receiver";
CM_ SG_ 2566734590 CertTypeFileServer "ISOBUS Compliance certification type - File server";
CM_ SG_ 2566734590 CertTypeTCWorkingSetMember "ISOBUS Compliance certification type - TC working set member";
CM_ SG_ 2566734590 CertTypeTCWorkingSetMaster "ISOBUS Compliance certification type - TC working set master";
CM_ SG_ 2566734590 CertTypeTaskController "ISOBUS Compliance certification type - Task Controller";
CM_ SG_ 2566734590 CertificationReferenceNumber "ISOBUS Compliance certification reference number";
CM_ BO_ 2566835198 "Previously active diagnostic trouble codes";
CM_ SG_ 2566835198 DTC1 "Diagnostic Trouble Code";
CM_ SG_ 2566835198 DTC2 "Diagnostic Trouble Code";
CM_ SG_ 2566835198 DTC3 "Diagnostic Trouble Code";
CM_ SG_ 2566835198 DTC4 "Diagnostic Trouble Code";
CM_ SG_ 2566835198 DTC5 "Diagnostic Trouble Code";
CM_ BO_ 2566834942 "Active diagnostic trouble codes";
CM_ SG_ 2566834942 DTC1 "Diagnostic Trouble Code";
CM_ SG_ 2566834942 DTC2 "Diagnostic Trouble Code";
CM_ SG_ 2566834942 DTC3 "Diagnostic Trouble Code";
CM_ SG_ 2566834942 DTC4 "Diagnostic Trouble Code";
CM_ SG_ 2566834942 DTC5 "Diagnostic Trouble Code";
CM_ BO_ 2566839038 "Software Identification";
CM_ SG_ 2566839038 NmbrOfSftwreIdentificationFields "Number of software identification designators represented in the software identification parameter group.";
CM_ SG_ 2566839038 SoftwareID1 "Software ID";
CM_ SG_ 2566839038 SoftwareID2 "Software ID";
CM_ SG_ 2566839038 SoftwareID3 "Software ID";
CM_ BO_ 2566768126 "ECU Identification Information";
CM_ SG_ 2566768126 ECUPartNumber "The part number of the physical ECU.";
CM_ SG_ 2566768126 ECUSerialNumber "The serial number of the physical ECU.";
CM_ SG_ 2566768126 ECULocation "The location of the ECU within a network.";
CM_ BO_ 2566838526 "Commanded Address";
CM_ SG_ 2566838526 AddressAssignment "The source address that is to be assigned to the CA that has the NAME corresponding to the one conveyed in the first eight bytes of this Commanded Address message.";
CM_ BO_ 2565799678 "Address Claimed";
CM_ BO_ 2565734142 "Used to access network interconnection ECU parametrics and database";
CM_ SG_ 2565734142 ToPort "Destination port for network PG";
CM_ SG_ 2565734142 FromPort "Source port for Network PG";
CM_ SG_ 2565734142 FilterMode "Filter mode for Network PG";
BA_DEF_ BU_  "ISO11783PDDVersion" ENUM  "0","1","2","3","4";
BA_DEF_ BU_  "ISO11783IOPVersion" ENUM  "0","1","2","3","4","5";
BA_DEF_ SG_  "GenSigStartValue" INT -2147483648 2147483647;
BA_DEF_  "ISO11783_13_SpecVersion" STRING ;
BA_DEF_  "ISO11783_12_SpecVersion" STRING ;
BA_DEF_ SG_  "SigType" ENUM  "Default","Range","RangeSigned","ASCII","Discrete","Control","ReferencePGN","DTC","StringDelimiter","StringLength","StringLengthControl";
BA_DEF_ SG_  "GenSigSendType" ENUM  "Cyclic","OnWrite","OnWriteWithRepetition","OnChange","OnChangeWithRepetition","IfActive","IfActiveWithRepetition","NoSigSendType";
BA_DEF_  "DatabaseVersion" STRING ;
BA_DEF_ SG_  "SPN" INT 0 524287;
BA_DEF_ BO_  "GenMsgCycleTimeFast" INT 0 3600000;
BA_DEF_ BO_  "GenMsgRequestable" INT 0 1;
BA_DEF_ BO_  "GenMsgCycleTime" INT 0 3600000;
BA_DEF_ BO_  "GenMsgSendType" ENUM  "cyclic","NotUsed","IfActive","NotUsed","NotUsed","NotUsed","NotUsed","NotUsed","noMsgSendType","vector_leerstring";
BA_DEF_ BO_  "VFrameFormat" ENUM  "StandardCAN","ExtendedCAN","reserved","J1939PG","vector_leerstring";
BA_DEF_ BU_  "ECU" STRING ;
BA_DEF_ BU_  "NmJ1939IdentityNumber" INT 0 2097151;
BA_DEF_ BU_  "NmJ1939ManufacturerCode" INT 0 2047;
BA_DEF_ BU_  "NmJ1939ECUInstance" INT 0 7;
BA_DEF_ BU_  "NmJ1939FunctionInstance" INT 0 7;
BA_DEF_ BU_  "NmJ1939Function" INT 0 255;
BA_DEF_ BU_  "NmJ1939SystemInstance" INT 0 15;
BA_DEF_ BU_  "NmJ1939System" INT 0 127;
BA_DEF_ BU_  "NmJ1939IndustryGroup" INT 0 7;
BA_DEF_ BU_  "NmJ1939AAC" INT 0 1;
BA_DEF_ BU_  "NmStationAddress" INT 0 255;
BA_DEF_  "BusType" STRING ;
BA_DEF_  "ProtocolType" STRING ;
BA_DEF_ BU_  "NodeLayerModules" STRING ;
BA_DEF_ BO_  "SingleFrame" INT 0 1;
BA_DEF_ SG_  "DDI" INT 0 65535;
BA_DEF_  "ISO11783_6_SpecVersion" STRING ;
BA_DEF_  "ISO11783_7_SpecVersion" STRING ;
BA_DEF_  "ISO11783_11_SpecVersion" STRING ;
BA_DEF_ SG_  "SystemSignalLongSymbol" STRING ;
BA_DEF_ EV_  "SystemEnvVarLongSymbol" STRING ;
BA_DEF_DEF_  "ISO11783PDDVersion" "3";
BA_DEF_DEF_  "ISO11783IOPVersion" "3";
BA_DEF_DEF_  "GenSigStartValue" 0;
BA_DEF_DEF_  "ISO11783_13_SpecVersion" "";
BA_DEF_DEF_  "ISO11783_12_SpecVersion" "";
BA_DEF_DEF_  "SigType" "Default";
BA_DEF_DEF_  "GenSigSendType" "NoSigSendType";
BA_DEF_DEF_  "DatabaseVersion" "";
BA_DEF_DEF_  "SPN" 0;
BA_DEF_DEF_  "GenMsgCycleTimeFast" 0;
BA_DEF_DEF_  "GenMsgRequestable" 1;
BA_DEF_DEF_  "GenMsgCycleTime" 0;
BA_DEF_DEF_  "GenMsgSendType" "noMsgSendType";
BA_DEF_DEF_  "VFrameFormat" "J1939PG";
BA_DEF_DEF_  "ECU" "";
BA_DEF_DEF_  "NmJ1939IdentityNumber" 0;
BA_DEF_DEF_  "NmJ1939ManufacturerCode" 0;
BA_DEF_DEF_  "NmJ1939ECUInstance" 0;
BA_DEF_DEF_  "NmJ1939FunctionInstance" 0;
BA_DEF_DEF_  "NmJ1939Function" 0;
BA_DEF_DEF_  "NmJ1939SystemInstance" 0;
BA_DEF_DEF_  "NmJ1939System" 0;
BA_DEF_DEF_  "NmJ1939IndustryGroup" 0;
BA_DEF_DEF_  "NmJ1939AAC" 0;
BA_DEF_DEF_  "NmStationAddress" 254;
BA_DEF_DEF_  "BusType" "";
BA_DEF_DEF_  "ProtocolType" "";
BA_DEF_DEF_  "NodeLayerModules" "";
BA_DEF_DEF_  "SingleFrame" 1;
BA_DEF_DEF_  "DDI" 0;
BA_DEF_DEF_  "ISO11783_6_SpecVersion" "";
BA_DEF_DEF_  "ISO11783_7_SpecVersion" "";
BA_DEF_DEF_  "ISO11783_11_SpecVersion" "";
BA_DEF_DEF_  "SystemSignalLongSymbol" "";
BA_DEF_DEF_  "SystemEnvVarLongSymbol" "";
BA_ "ISO11783_13_SpecVersion" "2010-01-29 2007 With Amendments ";
BA_ "BusType" "CAN";
BA_ "ISO11783_11_SpecVersion" "2007-04-01 IS";
BA_ "ISO11783_7_SpecVersion" "2009-01-29 FDIS";
BA_ "ISO11783_6_SpecVersion" "2010-05-11 FDIS";
BA_ "ProtocolType" "ISO11783";
BA_ "DatabaseVersion" "7.5 SP2";
BA_ "ISO11783_12_SpecVersion" "2010-04-14 IS (Corrected version)";
BA_ "ECU" BU_ VT "VT";
BA_ "NmJ1939ManufacturerCode" BU_ VT 1861;
BA_ "NmJ1939Function" BU_ VT 29;
BA_ "NmJ1939IndustryGroup" BU_ VT 2;
BA_ "NmJ1939AAC" BU_ VT 1;
BA_ "NmStationAddress" BU_ VT 38;
BA_ "ECU" BU_ OPC "OPC";
BA_ "NmJ1939IdentityNumber" BU_ OPC 701231;
BA_ "NmJ1939ManufacturerCode" BU_ OPC 1861;
BA_ "NmJ1939Function" BU_ OPC 255;
BA_ "NmJ1939IndustryGroup" BU_ OPC 2;
BA_ "NmJ1939AAC" BU_ OPC 1;
BA_ "NmStationAddress" BU_ OPC 128;
BA_ "NodeLayerModules" BU_ OPC "ISO11783_IL.dll";
BA_ "GenMsgSendType" BO_ 2365378048 0;
BA_ "GenMsgCycleTime" BO_ 2365378048 500;
BA_ "GenMsgCycleTimeFast" BO_ 2365378048 100;
BA_ "GenMsgSendType" BO_ 2566704384 0;
BA_ "GenMsgCycleTime" BO_ 2566704384 500;
BA_ "GenMsgCycleTime" BO_ 2314732286 250;
BA_ "GenMsgSendType" BO_ 2550660862 0;
BA_ "GenMsgCycleTime" BO_ 2550660862 100;
BA_ "GenMsgSendType" BO_ 2365408254 0;
BA_ "GenMsgCycleTime" BO_ 2365408254 100;
BA_ "SPN" SG_ 2365378048 RestoreOpDriveStratSetReq 5737;
BA_ "SPN" SG_ 2365378048 DriveStrategyPriority4Req 5736;
BA_ "SPN" SG_ 2365378048 DriveStrategyPriority3Req 5735;
BA_ "SPN" SG_ 2365378048 DriveStrategyPriority2Req 5734;
BA_ "SPN" SG_ 2365378048 DriveStrategyPriority1Req 5733;
BA_ "SPN" SG_ 2566704384 DriveStrategyRequestState 5731;
BA_ "SPN" SG_ 2566704384 DriveStrategyPriority4 5730;
BA_ "SPN" SG_ 2566704384 DriveStrategyPriority3 5729;
BA_ "SPN" SG_ 2566704384 DriveStrategyPriority2 5728;
BA_ "SPN" SG_ 2566704384 DriveStrategyPriority1 5727;
BA_ "SPN" SG_ 2566704384 DriveStrategyExitReason 5732;
BA_ "SPN" SG_ 2566843646 VehicleIdentificationNumber 237;
BA_ "SigType" SG_ 2566843646 VehicleIdentificationNumber 8;
BA_ "SystemSignalLongSymbol" SG_ 2559835902 ArbitraryAddressCapableQualifier "ArbitraryAddressCapableQualifierFlag";
BA_ "SystemSignalLongSymbol" SG_ 2559835902 VehicleSystemInstanceQualifierFl "VehicleSystemInstanceQualifierFlag";
BA_ "GenSigStartValue" SG_ 2358181630 GraphicsWidth 32;
BA_ "SigType" SG_ 2358181630 ActualVersionLabel 9;
BA_ "SigType" SG_ 2358181630 ActualConfigurationLabel 9;
BA_ "GenSigStartValue" SG_ 2358181630 GraphicsHeight 32;
BA_ "SigType" SG_ 2314732286 SID 1;
BA_ "SigType" SG_ 2314732286 COGReference 4;
BA_ "SigType" SG_ 2314732286 CourseOverGround 1;
BA_ "SigType" SG_ 2314732286 SpeedOverGround 1;
BA_ "SPN" SG_ 2365391360 StopAllImplementOperations 5140;
BA_ "SPN" SG_ 2365391616 ImplementOperatingStateCmd 5139;
BA_ "SPN" SG_ 2364547838 MachineSelectedSpeed 4305;
BA_ "SPN" SG_ 2364547838 MachineSelectedDistance 4306;
BA_ "SPN" SG_ 2364547838 MachineSelectedDirection 4309;
BA_ "SigType" SG_ 2364547838 MachineSelectedDirection 4;
BA_ "SPN" SG_ 2364547838 MachineSelectedSpeedSource 4308;
BA_ "SPN" SG_ 2364547838 MachineSelectedSpeedLimitStatus 4307;
BA_ "SPN" SG_ 2550660862 ValvePilotPress 4087;
BA_ "SigType" SG_ 2550660862 ValvePilotPress 1;
BA_ "SPN" SG_ 2550660862 ValveLoadSensePress 4086;
BA_ "SigType" SG_ 2550660862 ValveLoadSensePress 1;
BA_ "SPN" SG_ 2550660862 ValveAssemblySupplyPress 4089;
BA_ "SigType" SG_ 2550660862 ValveAssemblySupplyPress 1;
BA_ "SPN" SG_ 2550660862 ValveAssemblyLoadSensePress 4088;
BA_ "SigType" SG_ 2550660862 ValveAssemblyLoadSensePress 1;
BA_ "SystemSignalLongSymbol" SG_ 2566730494 StopAllImplementOperationsOption "StopAllImplementOperationsOptions";
BA_ "SystemSignalLongSymbol" SG_ 2566730494 AdvanceTECU_MotionInitiationOpti "AdvanceTECU_MotionInitiationOption";
BA_ "SPN" SG_ 2365408254 MachineSelSpeedSetpointCommand 4310;
BA_ "SigType" SG_ 2365408254 MachineSelSpeedSetpointCommand 1;
BA_ "SPN" SG_ 2365408254 MachineSelSpeedSetpointLimit 4311;
BA_ "SigType" SG_ 2365408254 MachineSelSpeedSetpointLimit 1;
BA_ "SPN" SG_ 2365408254 MachineSelDirectionCommand 4312;
BA_ "SigType" SG_ 2365408254 MachineSelDirectionCommand 4;
BA_ "SPN" SG_ 2566734590 CertificationYear 4313;
BA_ "SPN" SG_ 2566734590 CertificateRevision 4314;
BA_ "SPN" SG_ 2566734590 CertificateLaboratoryType 4315;
BA_ "SPN" SG_ 2566734590 CertificationLaboratoryID 4316;
BA_ "SPN" SG_ 2566734590 CertTypeVTWorkingSetMember 4324;
BA_ "SPN" SG_ 2566734590 CertTypeVTWorkingSetMaster 4323;
BA_ "SPN" SG_ 2566734590 CertTypeVirtualTerminal 4322;
BA_ "SPN" SG_ 2566734590 CertTypeClass3ECU 4321;
BA_ "SPN" SG_ 2566734590 CertTypeTECUClass3 4320;
BA_ "SPN" SG_ 2566734590 CertTypeTECUClass2 4319;
BA_ "SPN" SG_ 2566734590 CertTypeTECUClass1 4318;
BA_ "SPN" SG_ 2566734590 CertTypeMinimumECU 4317;
BA_ "SPN" SG_ 2566734590 CertTypeGPSReceiver 4329;
BA_ "SPN" SG_ 2566734590 CertTypeFileServer 4328;
BA_ "SPN" SG_ 2566734590 CertTypeTCWorkingSetMember 4327;
BA_ "SPN" SG_ 2566734590 CertTypeTCWorkingSetMaster 4326;
BA_ "SPN" SG_ 2566734590 CertTypeTaskController 4325;
BA_ "SPN" SG_ 2566734590 CertificationReferenceNumber 4330;
BA_ "SigType" SG_ 2566835198 DTC1 7;
BA_ "SigType" SG_ 2566835198 DTC2 7;
BA_ "SigType" SG_ 2566835198 DTC3 7;
BA_ "SigType" SG_ 2566835198 DTC4 7;
BA_ "SigType" SG_ 2566835198 DTC5 7;
BA_ "SigType" SG_ 2566834942 DTC1 7;
BA_ "SigType" SG_ 2566834942 DTC2 7;
BA_ "SigType" SG_ 2566834942 DTC3 7;
BA_ "SigType" SG_ 2566834942 DTC4 7;
BA_ "SigType" SG_ 2566834942 DTC5 7;
BA_ "SPN" SG_ 2566839038 NmbrOfSftwreIdentificationFields 965;
BA_ "SigType" SG_ 2566839038 NmbrOfSftwreIdentificationFields 1;
BA_ "SPN" SG_ 2566839038 SoftwareID1 234;
BA_ "SigType" SG_ 2566839038 SoftwareID1 8;
BA_ "SPN" SG_ 2566839038 SoftwareID2 234;
BA_ "SigType" SG_ 2566839038 SoftwareID2 8;
BA_ "SPN" SG_ 2566839038 SoftwareID3 234;
BA_ "SigType" SG_ 2566839038 SoftwareID3 8;
BA_ "SPN" SG_ 2566768126 ECUPartNumber 2901;
BA_ "SigType" SG_ 2566768126 ECUPartNumber 8;
BA_ "SPN" SG_ 2566768126 ECUSerialNumber 2902;
BA_ "SigType" SG_ 2566768126 ECUSerialNumber 8;
BA_ "SPN" SG_ 2566768126 ECULocation 2903;
BA_ "SigType" SG_ 2566768126 ECULocation 8;
BA_ "SPN" SG_ 2566768126 ECUType 2904;
BA_ "SigType" SG_ 2566768126 ECUType 8;
BA_ "SigType" SG_ 2566768126 ECUManufacturerName 8;
BA_ "SPN" SG_ 2566768126 ECUManufacturerName 4304;
BA_ "SPN" SG_ 2566838526 IdentityNumber 2837;
BA_ "SPN" SG_ 2566838526 ManufacturerCode 2838;
BA_ "SigType" SG_ 2566838526 ManufacturerCode 1;
BA_ "SPN" SG_ 2566838526 ECUInstance 2840;
BA_ "SPN" SG_ 2566838526 FunctionInstance 2839;
BA_ "SPN" SG_ 2566838526 Function 2841;
BA_ "SPN" SG_ 2566838526 VehicleSystemInstance 2843;
BA_ "SPN" SG_ 2566838526 IndustryGroup 2846;
BA_ "SPN" SG_ 2566838526 ArbitraryAddressCapable 2844;
BA_ "SPN" SG_ 2566838526 AddressAssignment 2847;
BA_ "SigType" SG_ 2566838526 AddressAssignment 1;
BA_ "SPN" SG_ 2565799678 IdentityNumber 2837;
BA_ "SPN" SG_ 2565799678 ManufacturerCode 2838;
BA_ "SigType" SG_ 2565799678 ManufacturerCode 1;
BA_ "SPN" SG_ 2565799678 ECUInstance 2840;
BA_ "SPN" SG_ 2565799678 FunctionInstance 2839;
BA_ "SPN" SG_ 2565799678 Function 2841;
BA_ "SPN" SG_ 2565799678 VehicleSystemInstance 2843;
BA_ "SPN" SG_ 2565799678 IndustryGroup 2846;
BA_ "SPN" SG_ 2565799678 ArbitraryAddressCapable 2844;
BA_ "SigType" SG_ 2565734142 ControlByte 1;
BA_ "SigType" SG_ 2565734142 FilterMode 1;
VAL_ 2365378048 RestoreOpDriveStratSetReq 3 "Not available " 2 "Error indication " 1 "Restore Operator Drive Strategy Setting " 0 "No Request (sent when implement does not want setting restored) " ;
VAL_ 2365378048 DriveStrategyPriority4Req 255 "Not available/Don't care " 254 "Error or reserved" 6 "Enable maximum electric power control" 5 "Enable maximum hydraulic power control" 4 "Enable engine economy control " 3 "Enable minimum engine speed control" 2 "Enable wheel speed/PTO speed ratio control" 1 "Enable constant PTO speed control" 0 "Enable maximum draft power control " ;
VAL_ 2365378048 DriveStrategyPriority3Req 255 "Not available/Don't care " 254 "Error or reserved" 6 "Enable maximum electric power control" 5 "Enable maximum hydraulic power control" 4 "Enable engine economy control " 3 "Enable minimum engine speed control" 2 "Enable wheel speed/PTO speed ratio control" 1 "Enable constant PTO speed control" 0 "Enable maximum draft power control " ;
VAL_ 2365378048 DriveStrategyPriority2Req 255 "Not available/Don't care " 254 "Error or reserved" 6 "Enable maximum electric power control" 5 "Enable maximum hydraulic power control" 4 "Enable engine economy control " 3 "Enable minimum engine speed control" 2 "Enable wheel speed/PTO speed ratio control" 1 "Enable constant PTO speed control" 0 "Enable maximum draft power control " ;
VAL_ 2365378048 DriveStrategyPriority1Req 255 "Not available/Don't care " 254 "Error or reserved" 6 "Enable maximum electric power control" 5 "Enable maximum hydraulic power control" 4 "Enable engine economy control " 3 "Enable minimum engine speed control" 2 "Enable wheel speed/PTO speed ratio control" 1 "Enable constant PTO speed control" 0 "Enable maximum draft power control " ;
VAL_ 2566704384 DriveStrategyRequestState 3 "Not available/Not Installed " 2 "Error indication " 1 "Control override (most recent external request ignored)" 0 "External Request Accepted. No subsequent operator intervention" ;
VAL_ 2566704384 DriveStrategyPriority4 255 "Not available/Don't care " 254 "Error or reserved" 253 "Requested mode not supported " 6 "Enable maximum electric power control" 5 "Enable maximum hydraulic power control" 4 "Enable engine economy control " 3 "Enable minimum engine speed control" 2 "Enable wheel speed/PTO speed ratio control" 1 "Enable constant PTO speed control" 0 "Enable maximum draft power control " ;
VAL_ 2566704384 DriveStrategyPriority3 255 "Not available/Don't care " 254 "Error or reserved" 253 "Requested mode not supported " 6 "Enable maximum electric power control" 5 "Enable maximum hydraulic power control" 4 "Enable engine economy control " 3 "Enable minimum engine speed control" 2 "Enable wheel speed/PTO speed ratio control" 1 "Enable constant PTO speed control" 0 "Enable maximum draft power control " ;
VAL_ 2566704384 DriveStrategyPriority2 255 "Not available/Don't care " 254 "Error or reserved" 253 "Requested mode not supported " 6 "Enable maximum electric power control" 5 "Enable maximum hydraulic power control" 4 "Enable engine economy control " 3 "Enable minimum engine speed control" 2 "Enable wheel speed/PTO speed ratio control" 1 "Enable constant PTO speed control" 0 "Enable maximum draft power control " ;
VAL_ 2566704384 DriveStrategyPriority1 255 "Not available/Don't care " 254 "Error or reserved" 253 "Requested mode not supported " 6 "Enable maximum electric power control" 5 "Enable maximum hydraulic power control" 4 "Enable engine economy control " 3 "Enable minimum engine speed control" 2 "Enable wheel speed/PTO speed ratio control" 1 "Enable constant PTO speed control" 0 "Enable maximum draft power control " ;
VAL_ 2566704384 DriveStrategyExitReason 63 "Not available (parameter not supported) " 62 "Error " 22 "Vehicle transmission gear does not allow remote commands" 9 "Function fault " 8 "Operator control fault" 7 "Function not calibrated " 6 "Remote command out of range/invalid " 5 "Remote command timeout" 4 "Operator control not in valid position" 3 "Operator override of function " 2 "Implement released control of function " 1 "Operator presence not detected " 0 "No reason/all clear " ;
VAL_ 2559835902 ErrorCode 5 "Other" 255 "Not Available" 4 "Pending Name not set" 3 "Checksum does not match" 2 "Item conflict" 1 "Item(s) not allowed to change" 0 "Security not satisfied" ;
VAL_ 2559835902 NMControlModeIndicator 8 "ReqNameAddressClaim" 7 "AdoptPendingName" 6 "ReqCurrentName" 5 "ReqPendingName" 4 "NameNACK" 3 "NameACK" 2 "CurrentName" 1 "PendingName" 0 "SetPendingName" ;
VAL_ 2358116094 MessageCode 150 "SCClientStatus" 145 "SCMasterMemoryRequest" 144 "SCMasterCapabilityRequest" 53 "SCClientFunctionErrorResponse" 52 "SCClientExecutionStatus" 50 "SCExecutionIndication" 49 "SCClientAbort" 7 "SCDLoadCommand" 6 "SCDStoreCommand" 5 "SCDDeleteCommand" 4 "SCDActivationCommand" 3 "SCDTransfer" 2 "SCDConfigurationLabelRequest" 1 "SCDVersionRequest" ;
VAL_ 2358116094 DeleteCommandType 1 "DeleteSCDInNonVolatileMemory" 0 "DeleteSCDInVolatileMemory" ;
VAL_ 2358116094 SCCState 2 "Initialization" 1 "Enabled" 0 "Disabled" ;
VAL_ 2358116094 SequenceNumber 255 "NoSequenceAvailable" ;
VAL_ 2358116094 NewFunctionExecutionState 3 "ErrorDuringExecution" 2 "FunctionExecutionCompleted" 1 "FunctionExecutionStarted" 0 "FunctionExecStartedAndCompleted" ;
VAL_ 2358116094 FunctionExecutionState 3 "ErrorDuringExecution" 2 "FunctionExecutionCompleted" 1 "FunctionExecutionStarted" 0 "FunctionExecStartedAndCompleted" ;
VAL_ 2358116094 SequenceState 255 "SequenceStateNotAvailable" 5 "Abort" 4 "PlayBack" 2 "Recording" 1 "Ready" ;
VAL_ 2358116094 ClientAbortError 255 "GeneralError" 3 "ErrorDuringFunctionExecution" 2 "OperatorInteraction" 1 "TimeoutOnStatusMessage" ;
VAL_ 2358116094 ClientFunctionErrorStatuts1 15 "GeneralError" 4 "ClientFunctionIsDeactivated" 3 "ClientFunctionIsLocked" 2 "PermanentError" 1 "OneTimeError" ;
VAL_ 2358116094 ClientExecutionError 255 "GeneralError" 3 "ConditionsOfSCCAllowNoExecution" 2 "OperatorInteraction" 1 "ErrorInTheFunction" 0 "NoError" ;
VAL_ 2358116094 OperatorConfirmationRequired1 1 "yes" 0 "no" ;
VAL_ 2358116094 ClientFunctonErrorState 255 "ErrorStateNotAvailable" 3 "ErrorStateReqConfirmationChanged" 2 "ErrorStateChanged" 1 "ErrorStateNotChanged" 0 "NoError" ;
VAL_ 2358116094 ClientFunctionErrorStatuts2 15 "GeneralError" 4 "ClientFunctionIsDeactivated" 3 "ClientFunctionIsLocked" 2 "PermanentError" 1 "OneTimeError" ;
VAL_ 2358116094 OperatorConfirmationRequired2 1 "yes" 0 "no" ;
VAL_ 2358116094 ClientFunctionErrorStatuts3 15 "GeneralError" 4 "ClientFunctionIsDeactivated" 3 "ClientFunctionIsLocked" 2 "PermanentError" 1 "OneTimeError" ;
VAL_ 2358116094 OperatorConfirmationRequired3 1 "yes" 0 "no" ;
VAL_ 2358181630 MessageCode 149 "SCMasterStatus" 145 "SCMasterMemoryResponse" 144 "SCMasterCapablilityResponse" 53 "SCClientFunctionErrorRequest" 52 "SCClientExecutionAcknowledgement" 51 "SCMasterExecutionCommand" 50 "SCExecutionIndicationResponse" 48 "SCStateCommand" 7 "SCDLoadResponse" 6 "SCDStoreResponse" 5 "SCDDeleteResponse" 4 "SCDActivationResponse" 3 "SCDTransferResponse" 2 "SCDConfigurationLabelResponse" 1 "SCDVersionResponse" ;
VAL_ 2358181630 LoadResponseError 255 "GeneralError" 3 "NotEnoughVolatileMemoryAvailable" 2 "FileSystemErrorOrDataCorruption" 1 "SCDNotFound" 0 "NoError" ;
VAL_ 2358181630 StoreCommandError 255 "GeneralError" 2 "NotEnoughNonVolatileMemory" 1 "SCDWasNotCompletelyParsed" 0 "NoError" ;
VAL_ 2358181630 DeleteCommandResponseError 255 "GeneralError" 1 "SCDDoesNotExist" 0 "NoError" ;
VAL_ 2358181630 CommandedSCCState 1 "Enabled" 0 "Disabled" ;
VAL_ 2358181630 SCVersion 2 "IS" 1 "FDIS" 0 "DIS" ;
VAL_ 2358181630 SCMState 2 "Initialization" 1 "Active" 0 "Inactive" ;
VAL_ 2358181630 ActivationResponseError 255 "GeneralError" 14 "SCVersionNotSupportedBySCM" 13 "SCDConfigLabelLengthIncorrect" 12 "SCDVersionLabelLengthIncorrect" 11 "InvalidGraphicObject" 10 "DesignatorStringthLengthIsZero" 9 "StateIDIsNotUnique" 8 "FunctionIDIsNotUnique" 7 "ObjectIDIsNotUnique" 6 "ReferencedGraphObjDoesNotExist" 5 "ReferencedStringObjDoesNotExist" 4 "ReferencedStateObjDoesNotExist" 3 "ReferencedFunctObjDoesNotExist" 2 "BasicObjectDoesNotExist" 1 "UnknownObjectType" 0 "NoError" ;
VAL_ 2358181630 TransferResponseError 255 "GeneralError" 1 "ErrorOccurredDuringTransfer" 0 "NoError" ;
VAL_ 2358181630 ConfigLabelResponseError 255 "GeneralError" 1 "NoMatchingSCDStored" 0 "NoError" ;
VAL_ 2358181630 VersionResponseError 255 "GeneralError" 1 "NoMatchingSCDStored" 0 "NoError" ;
VAL_ 2358181630 MemoryStatus 1 "NotEnoughMemoryAvailable" 0 "EnoughMemoryAvailable" ;
VAL_ 2358181630 SequenceNumber 255 "NoSequenceAvailable" ;
VAL_ 2358181630 FunctionExecutionStateAck 3 "AckErrorDuringExecution" 2 "AckOfFunctionExecutionCompleted" 1 "AckOfFunctionExecutionStarted" 0 "AckOfFuncExecStartAndCompletion" ;
VAL_ 2358181630 FunctionExecutionState 3 "ErrorDuringExecution" 2 "FunctionExecutionCompleted" 1 "FunctionExecutionStarted" 0 "FunctionExecStartedAndCompleted" ;
VAL_ 2358181630 ReasonIndicator 255 "NoSpecificReason" 3 "SCCIsPartOfSelectedSCS" 2 "SCCNotPartOfSelectedSCS" 1 "StatusChangeOnOperatorCommand" ;
VAL_ 2358181630 SequenceState 255 "SequenceStateNotAvailable" 5 "Abort" 4 "PlayBack" 3 "RecordingCompletition" 2 "Recording" 1 "Ready" ;
VAL_ 2358181630 ExecutionIndicationResponseError 255 "GeneralError" 6 "PlayBackHaltedDueToOperator" 5 "PlayBackContinues" 4 "SCMOutOfMemory" 3 "FunctionExecutionStateMismatch" 2 "StateIDNotDefined" 1 "FunctionIDNotDefined" 0 "NoError" ;
VAL_ 2358181630 BusyFlagMemoryAccess 1 "BusyWithNonVolatileMemoryAccess" 0 "NotBusy" ;
VAL_ 2358181630 BusyFlagParsing 1 "SCMIsParsingAnSCD" 0 "NotBusy" ;
VAL_ 2314732286 SID 255 "nVldPsFxTTItTRng0T250FrVldPstnFx" ;
VAL_ 2314732286 COGReference 3 "Null" 2 "Error" 1 "Magnetic" 0 "True" ;
VAL_ 2365391360 StopAllImplementOperations 3 "NotAvailable " 2 "ErrorIndication" 1 "PermitAllImplementsToON " 0 "StopImplementOperations" ;
VAL_ 2365391616 ImplementOperatingStateCmd 3 "TakeNoAction" 2 "SetImplementToParkState" 1 "SetImplementToTransportState" 0 "SetImplementToFieldWorkingState" ;
VAL_ 2364547838 MachineSelectedDirection 3 "NotAvailable" 2 "ErrorIndication" 1 "Forward" 0 "Reverse" ;
VAL_ 2364547838 MachineSelectedSpeedSource 7 "NotAvailable" 6 "Reserved" 5 "Reserved" 4 "SimulatedSpeed" 3 "BlendedSpeed" 2 "NavigationBasedSpeed" 1 "GroundBasedSpeed" 0 "WheelBasedSpeed" ;
VAL_ 2364547838 MachineSelectedSpeedLimitStatus 7 "NotAvailable" 6 "NonRecoverableFault" 5 "Reserved" 4 "Reserved" 3 "LimitedLow" 2 "LimitedHigh" 1 "OperatorLimited_Controlled" 0 "NotLimited" ;
VAL_ 2566730494 FirstListedFuncCharacteristic 254 "Not available" 253 "Error indication" 24 "Diagnostic ECU " 23 "Diagnostic tool " 22 "Stop all implement operations implement set " 21 "Stop all implement operations input" 20 "Sequence control client " 19 "Sequence control server" 18 "File server client " 17 "File server " 16 "Advance Tractor ECU implement set " 15 "Advance Tractor ECU  " 14 "Basic Tractor ECU implement set " 13 "Basic Tractor ECU  " 12 "Task controller section control working set " 11 "Task controller section control " 10 "Task controller geo working set " 9 "Task controller geo  " 8 "Task controller basic working set " 7 "Task controller basic" 6 "Auxiliary control Type 2 functions" 5 "Auxiliary control Type 2 inputs " 4 "Auxiliary control Type 1 functions " 3 "Auxiliary control Type 1 inputs " 2 "Virtual terminal working set " 1 "Virtual terminal " 0 "No functionalities reported " ;
VAL_ 2365408254 MachineSelDirectionCommand 3 "DontCare" 2 "Reserved" 1 "Forward" 0 "Reverse" ;
VAL_ 2566734590 CertTypeTCSectionControlWSMember 1 "Certification test performed" 0 "Not certified" ;
VAL_ 2566734590 CertTypeTCSectionControl 1 "Certification test performed" 0 "Not certified" ;
VAL_ 2566734590 CertTypeSeqControlMaster 1 "Certification test performed" 0 "Not certified" ;
VAL_ 2566734590 CertTypeSecControlClient 1 "Certification test performed" 0 "Not certified" ;
VAL_ 2566734590 CertTypeFileClient 1 "Certification test performed" 0 "Not certified" ;
VAL_ 2566734590 CertTypeDataLoggerWSMember 1 "Certification test performed" 0 "Not certified" ;
VAL_ 2566734590 CertTypeDataLoggerWSMaster 1 "Certification test performed" 0 "Not certified" ;
VAL_ 2566734590 CertTypeDataLogger 1 "Certification test performed" 0 "Not certified" ;
VAL_ 2566734590 CertTypeAuxControlInUnit 1 "Certification test performed" 0 "Not certified" ;
VAL_ 2566734590 CertTypeAuxControlFunc 1 "Certification test performed" 0 "Not certified" ;
VAL_ 2566734590 CertificateRevision 3 "NotAvailable" 2 "ThirdRevision" 1 "SecondRevision" 0 "FirstRevision" ;
VAL_ 2566734590 CertificateLaboratoryType 7 "Not available (not certified) " 2 "Reserved " 1 "AEF certified laboratory " 0 "Non-certified Laboratory" ;
VAL_ 2566734590 CertTypeVTWorkingSetMember 1 "CertificationTestPerformed" 0 "NotCertified" ;
VAL_ 2566734590 CertTypeVTWorkingSetMaster 1 "CertificationTestPerformed" 0 "NotCertified" ;
VAL_ 2566734590 CertTypeVirtualTerminal 1 "CertificationTestPerformed" 0 "NotCertified" ;
VAL_ 2566734590 CertTypeClass3ECU 1 "CertificationTestPerformed" 0 "NotCertified" ;
VAL_ 2566734590 CertTypeTECUClass3 1 "CertificationTestPerformed" 0 "NotCertified" ;
VAL_ 2566734590 CertTypeTECUClass2 1 "CertificationTestPerformed" 0 "NotCertified" ;
VAL_ 2566734590 CertTypeTECUClass1 1 "CertificationTestPerformed" 0 "NotCertified" ;
VAL_ 2566734590 CertTypeMinimumECU 1 "CertificationTestPerformed" 0 "NotCertified" ;
VAL_ 2566734590 CertTypeGPSReceiver 1 "CertificationTestPerformed" 0 "NotCertified" ;
VAL_ 2566734590 CertTypeFileServer 1 "CertificationTestPerformed" 0 "NotCertified" ;
VAL_ 2566734590 CertTypeTCWorkingSetMember 1 "CertificationTestPerformed" 0 "NotCertified" ;
VAL_ 2566734590 CertTypeTCWorkingSetMaster 1 "CertificationTestPerformed" 0 "NotCertified" ;
VAL_ 2566734590 CertTypeTaskController 1 "CertificationTestPerformed" 0 "NotCertified" ;
VAL_ 2566734590 CertificationReferenceNumber 1 "CertificationTestPerformed" 0 "NotCertified" ;
VAL_ 2566838526 ManufacturerCode 454 "NGK Spark Plug Co. Ltd" 453 "Cooper Bussmann" 452 "WIKA Alexander Wiegand SE & Co. KG" 451 "Parker Hannifin Corp" 450 "Dycor Technologies Ltd." 449 "Polaris Industries Inc" 448 "Stanadyne Corporation, Electronics Systems" 447 "Great Plains Mfg." 446 "CertTech, L.L.C." 445 "KAT MECHATRONIC, Electronic Product Division" 444 "ITT Power Solutions" 443 "SignalQuest, Inc." 442 "Horsch Maschinen GmbH" 441 "PTG Reifendruckregelsysteme GmbH" 440 "Cummins Power Generation" 439 "Hyundai Heavy Industries" 438 "Comar Systems Ltd" 437 "Digital Yacht Limited" 436 "Kinze Manufacturing" 435 "Zunhammer GmbH" 434 "Stored Energy Systems" 433 "Rowe Electronics" 432 "S&A Systems, Inc." 431 "Tohatsu Corporation" 430 "Auteq Telematica S.A." 479 "Vapor Bus International" 478 "OceanSat BV" 477 "OilQuick AB" 476 "Hummingbird Marine Electronics" 475 "GME" 474 "Persen Technologies Inc." 473 "Boss Industries, Inc." 472 "Tenneco Inc." 471 "Sea Cross Marine AB" 470 "SI-TEX Marine Electronics" 469 "RA Consulting GmbH" 468 "Tyco Fire Protection Products" 467 "Lely Industries N.V." 466 "Veethree Electronics and Marine LLC" 465 "Ashcroft Inc" 464 "Leach International Corporation" 463 "PROBOTIQ" 462 "IHI Shibaura Machinery Corporation" 461 "HAWE Hydraulik SE" 460 "San Giorgio S.E.I.N." 459 "Alltek Marine Electronics Corp" 458 "Control Solutions, Inc." 457 "RUSELPROM-ElectricDrive Ltd" 456 "General Kinetics" 455 "ADZ NAGANO GmbH" 429 "Rota Engineering Ltd." 428 "Mfg_428" 427 "Mfg_427" 426 "Mfg_426" 425 "Methode Electronics Inc, MDI" 424 "Odyne LLC" 423 "BSM Wireless, Inc." 422 "True Heading AB" 421 "Vertex Standard Co., Ltd" 420 "Vermeer Corporation, ACS Group" 419 "Fusion Electronics Ltd" 418 "Intellistick Inc" 417 "KZValve" 416 "Kubota Corporation" 415 "Valid Manufacturing Ltd." 414 "Cattron Group International" 413 "Datapross Nijbroek bv" 412 "WebTech Wireless Inc." 411 "Hy-Drive Technologies Ltd." 410 "COBO S.p.A. Divisione 3B6" 409 "Transfluid S.r.L." 408 "Corvus Energy Ltd." 407 "Comtech Mobile Datacom" 406 "Vecima Networks Inc." 405 "Wema System AS" 404 "Com Nav Marine Ltd" 403 "Trackwell ADS, Inc." 402 "Simma Software, Inc." 401 "Torqeedo GmbH" 400 "Livorsi Marine" 399 "ISEKI & Co., Ltd." 398 "Hilite International" 397 "Sanyo-kiki Co Ltd." 396 "Beyond Measure" 395 "GENTEC S.R.L." 394 "Capi 2 Nederland BV" 393 "Harvest Tec, Inc" 392 "Tianyuan Technology Co Ltd." 391 "Electronic Design for Industry, Inc" 390 "Partech Inc." 389 "Benchmark Electronics, Minnesota Division" 388 "Innomatix, LLC" 387 "Orscheln Products, LLC" 386 "JLG Automation BVBA" 385 "Johnson Outdoor Marine Electronics" 384 "Camano Light" 383 "MCL Industries" 382 "National Agricultural and Food Research Organization" 380 "Suntech International Ltd." 379 "Yamabiko Corporation" 378 "Glendinning Marine Products" 377 "ifm electronic gmbh" 376 "Quake Global" 375 "Williams Controls Inc." 372 "Delphi" 381 "B&G" 374 "Northern Lights, Inc." 373 "Electronic Design Inc." 371 "Heinzmann GmbH & Co. KG" 370 "Rolls-Royce Marine AS" 369 "Power Torque Engineering Ltd" 368 "HANSENHOF_electronic" 367 "Fliegl Agrartechnik" 366 "Viewnyx Corp." 365 "Digi-Star, LLC" 364 "OEM Controls Inc." 363 "BEI Duncan" 362 "Alois Poettinger Maschinenfabrik GmbH" 361 "InMach" 360 "HJS Emission Technology GmbH & Co KG" 359 "Ludwig Bergmann GmbH" 358 "Victron Energy BV" 357 "Hardi International A/S" 356 "Fischer Panda Generators, Inc" 355 "Mastervolt International B.V." 354 "Junkkari OY" 353 "Hegemon Electronics, Inc." 352 "SAME DEUTZ-FAHR" 351 "Thrane & Thrane" 350 "Noris Marine Systems GmbH & Co KG" 349 "Suonentiet" 348 "Amazonen Werke H. Dreyer" 347 "Honeywell" 346 "Control Solutions" 345 "Korean Maritime University" 344 "Parvus Corporation" 343 "Baumer Group" 342 "THOMAS MAGNETE GmbH" 341 "Boning GmbH & Co" 340 "Continental AG" 339 "Competence Center ISOBUS e.V." 338 "GRAF-SYTECO" 337 "Carraro S.p.A." 336 "APE s.r.o." 335 "Evo Electric Ltd" 334 "Takata-Petri AG" 333 "Hadley Products Corporation" 332 "HWH Corporation" 331 "Horton, Inc." 330 "Kidde Aerospace and Defense" 329 "Deif A/S" 328 "Qwerty Electronik AB" 252 "Sensor-Technik Wiedemann GmbH" 251 "German Agricultural Society" 250 "Kuhn Group" 249 "Schaltbau GmbH" 233 "Yacht Monitoring Solutions Inc." 232 "TSD Integrated Controls" 1863 "Thomas G. Faria Co." 1862 "Sanshin" 1861 "Vector North America" 1860 "MMP" 1859 "Kvasar AB" 1858 "Litton" 1857 "Simrad" 1856 "Trimble" 1855 "Furuno USA" 1854 "Northstar Technologies" 1853 "Japan Radio Co." 1852 "Navionics" 1851 "Raymarine" 1850 "Teleflex" 222 "Generac Power Systems, Inc." 221 "SiE" 220 "Beede Electrical Instrument Company, Inc." 219 "Cat OEM Solutions" 218 "Gits Manufacturing Company" 217 "RM Michaelides Software & Elektronik GmbH" 216 "Paneltronics Inc." 215 "Aetna Engineering/Fireboy-Xintex" 214 "MC elettronica Srl" 213 "CNH Belgium N.V." 212 "Sure Power Industries, Inc." 211 "DNA Group" 210 "Iteris, Inc." 209 "Bell Equip. Co. SA (PTY) LTD" 208 "Drew Technologies, Inc." 207 "Otto Engineering" 206 "port GmbH" 205 "SmarTire Systems Inc" 204 "The Morey Corporation" 203 "MILtronik GmbH" 202 "Curtis Instruments, Inc." 201 "Disenos y Tecnologia S.A." 200 "MGM Brakes" 199 "Actia Corp." 198 "Mystic Valley Communications" 197 "Mechron Power Systems" 196 "LEMKEN GmbH & Co. KG" 195 "General Engine Products" 194 "TriMark Corporation" 193 "Nobletec" 192 "Floscan" 191 "XATA Corporation" 190 "Hella KGaA Hueck & Co." 189 "QUALCOMM" 188 "EMP Corp." 187 "Air-Weigh" 186 "Altronic, Inc." 185 "Beede Electrical Instrument Company" 184 "EIA Electronics" 183 "KDS Controls, Inc." 182 "Vehicle Systems Engineering B.V." 181 "Coretronics, Inc." 180 "Smart Power Systems" 179 "TeeJet Technologies Denmark" 178 "Siemens VDO Automotive AG" 177 "Diagnostic System Associates" 176 "Moritz Aerospace" 175 "Veris Technologies, Inc." 174 "AB Volvo Penta" 173 "Ryeso, Inc." 172 "Yanmar Marine USA" 171 "Wachendorff Elektronik GmbH & Co. KG" 170 "Computronics Corporation Ltd." 169 "Marlin Technologies Inc." 168 "Xantrex" 167 "JLG Industries Inc." 166 "Phoenix International" 165 "CPAC Systems AB" 164 "DaimlerChrysler Off-Highway" 163 "BRP Inc." 162 "Axiomatic Technologies" 161 "Offshore Systems (UK) Limited" 160 "Nido" 159 "NTech Industries Inc." 158 "Firestone Industrial Products Company" 157 "ISSPRO Inc." 156 "ITT Industries - Cannon" 155 "Vetronix Corporation" 154 "Westerbeke Corporation" 153 "Woodward, Industrial Controls Division" 152 "elobau GmbH & Co. KG" 151 "Raven Industries Inc. - Flow Controls Division" 150 "Fleetguard" 149 "Holset" 148 "Blue Water Data, Inc." 147 "Nautibus Electronic GmbH" 146 "Maxima Technologies" 145 "MurCal Controls" 144 "Mercury Marine" 143 "W. Gmeiner GmbH & Co." 142 "TRW Automotive (Commercial Steering Systems)" 141 "Thales Navigation Ltd." 140 "Lowrance Electronics, Inc." 139 "Caterpillar Trimble Control Technologies (CTCT), LLC" 138 "Georg Fritzmeier GmbH & Co. KG" 137 "Maretron" 136 "Komatsu Ltd." 135 "Airmar Technology Corporation" 134 "Iris Technology Ltd." 133 "Bucher Schoerling GmbH" 132 "Mulag-Fahrzeugwerk" 131 "ITT Industries" 130 "Nido - Universal Machines B.V." 129 "OMNEX Control Systems, Inc." 128 "Gerhard Duecker GmbH & Co. KG" 127 "Holland USA" 126 "Driver Tech" 125 "Nevada Automotive Test Center" 124 "Hydac Electronic" 123 "Basler Electric" 122 "FG Wilson (Engineering) Limited" 121 "HED (Hydro Electronic Devices, Inc.)" 120 "RDS Technology Ltd." 119 "IntegriNautics" 118 "Intron GmbH" 117 "HUSCO International" 116 "BEELINE Technologies" 115 "NACCO Materials Handling Group, Inc." 114 "EControls, Inc." 113 "Stress-Tek, Inc." 112 "MECALAC" 111 "Maschinenfabrik Bernard Krone GmbH" 110 "EPIQ Sensor-Nite" 109 "TeeJet Technologies Denmark" 108 "WTK-Elecktronik GmbH" 107 "Grimme Landmaschinen GmbH & Co. KG" 106 "BAE Systems Controls, Inc." 105 "Kiepe Elektrik GmbH & Co. KG" 104 "Claas Selbstfahrende Erntemaschinen GmbH" 103 "CLAAS Agrosystems GmbH & Co. KG" 102 "AGCO GmbH & Co." 101 "Sensoria" 100 "VDO Technik AG" 99 "International Transmissions Ltd (ITL)" 98 "Mueller-Elektronik GmbH & Co." 97 "Ag Leader Technology, Inc." 96 "Mech@tronic IT GmbH" 95 "Pacific Insight Electronics Corp." 94 "CNH Global N.V." 93 "Perkins Engines Company Ltd." 92 "Ag-Chem Equipment Co., Inc." 91 "BSG Bodensee Steuergeraete GmbH" 90 "Knorr-Bremse SfN GmbH" 89 "Kverneland Group, Electronics Division" 88 "Satloc Precision GPS" 87 "J.C. Bamford Excavators Ltd (JCB)" 86 "C.E. Niehoff & Company" 85 "Kohler Co." 84 "New Holland UK Limited" 83 "Eaton VORAD Technologies" 82 "Bobcat/Ingersoll-Rand" 81 "Fire Research Corp" 80 "Twin Disc, Inc." 79 "Daimler Benz AG - Engine Division (PBM)" 78 "Frank W. Murphy Manufacturing, Inc." 77 "Deere Power Systems Group" 76 "unused" 75 "Deere & Co. Agricultural Division" 74 "Eaton Axle-Brake Division" 73 "LeTourneau, Inc." 72 "Sisu Corporation" 71 "Vansco Electronics Ltd." 70 "Flex-Coil Limited" 69 "Trimble Navigation" 68 "Scania" 67 "Funk Manufacturing Company" 66 "John Deere Construction Equipment Division" 65 "MAN Nutzfahrzeuge AG" 64 "unused" 63 "ZF Industries Inc." 62 "Wabco" 61 "Volvo Truck Corp." 60 "Volvo Trucks North America Inc." 59 "VES Inc." 58 "SPX Corporation, OTC Division" 57 "Sauer-Danfoss Co." 56 "SAIC" 55 "Ryder System Inc." 54 "Meritor Wabco" 53 "Continental Automotive Systems US, Inc." 52 "Meritor Automotive, Inc." 51 "Robert Bosch GmbH" 50 "Robert Bosch Corp" 49 "RE America Inc." 48 "Pollak Alphabet" 47 "Phillips Semiconductor" 46 "Noregon Systems, Inc" 45 "PACCAR" 44 "Nippondenso Co. Ltd." 43 "International Truck and Engine Corp. Vehicle Electronics" 42 "International Truck and Engine Corp. Engine Electronics" 41 "Motorola Inc." 40 "Motorola AIEG Inc." 39 "Microfirm Inc." 38 "Micro Processor Systems Inc." 37 "Mack Trucks Inc." 36 "Lucas Ltd." 35 "Kenworth Truck Co." 34 "Kelsey Hayes Co." 33 "John Deere" 32 "Jacobs Vehicle Systems" 31 "J Pollak Corp." 30 "Isuzu Motors Ltd." 29 "Hino Motors Ltd." 28 "Grote Ind. Inc." 27 "GMC" 26 "General Motors Corp., Service Technology Group" 25 "Daimler Trucks North America LLC" 24 "Ford Motor Co., Vehicle Controls" 23 "Ford Motor Co., Heavy Truck" 22 "Ford Motor Co., Electronic Concepts $ Systems" 21 "Echilin Inc., Midland Brake Inc." 20 "Eaton Ltd" 19 "Eaton Corp. Trucking Info Services" 18 "Eaton Corp, Transmission Division" 17 "Eaton Corp. Res & Dev" 16 "Eaton Corp." 15 "Dickey-John Corp." 14 "Detroit Diesel Corporation" 13 "Delco Electronics" 12 "Deere & Company, Precision Farming" 11 "Dearborn Group Inc." 10 "Cummins Engine Co." 9 "Chrysler Corp." 8 "Caterpillar Inc." 7 "Case Corp." 6 "Berifors Electronics AB" 5 "AMP Inc." 4 "Ametek-Dixson" 3 "Ametek, US Gauge Division" 2 "Allison Transmission, GMC" 1 "Allied Signal Inc." 0 "Reserved" 231 "Topcon Positioning Systems, Inc." 230 "Saucon Technologies" 229 "Garmin International Inc." 228 "ZF Marine Electronics" 227 "Lykketronic A/S" 226 "Monaco Coach Corporation" 225 "SKF" 224 "EMMI Network, S.L." 223 "Vaueo Retarder Co., Ltd." 263 "IMMI" 262 "HydraForce, Inc" 261 "Red Dot Corporation" 260 "Reichhardt GmbH" 259 "Jetter AG" 258 "ARAG" 257 "Honda Motor Co., Ltd" 256 "Tyco Electronics AMP" 255 "MEAS France" 254 "GE Sensing" 253 "Mobile Control Systems" 298 "Holley Performance" 297 "Zonar Systems Inc" 296 "micro dynamics GmbH" 295 "BEP Marine" 294 "Grayhill Inc." 293 "Spyder Controls Corp." 292 "IKUSI - Angel Iglesias S.A." 291 "Groeneveld Transport Efficiency BV" 290 "Kuebler GmbH" 289 "Watlow" 288 "Mitsubishi FUSO Truck & Bus Corp." 287 "NTech Industries, Inc" 286 "Coelmo srl" 285 "Sea Recovery Corp" 284 "Mobile Tech Chile" 283 "CWF Hamilton & Co Ltd" 282 "Medallion Instrumentation Systems" 281 "Precision Governors LLC" 311 "Patrick Power Products" 310 "TECNORD srl" 309 "Krauss-Maffei Wegmann GmbH & Co. KG" 308 "Cyntrx" 307 "MAS Technologies" 306 "Sleipner Motor AB" 305 "NovAtel Inc" 304 "EmpirBus AB" 303 "CTS Corporation" 302 "Nissin Kogyo Co., LTD" 301 "Parker Hannifin (UK) Ltd FDE group" 300 "Systron Donner Automotive" 299 "Rauch Landmaschinen GmbH" 280 "Leica Geosystems Pty Ltd" 279 "Geometris LP" 278 "Takata Electronics" 277 "LHP Telematics" 276 "Aqua-Hot Heating Systems" 275 "Navico Egersund AS" 274 "LTW Technology Co., LTD" 273 "Active Research Limited" 272 "Gross Mechanical Laboratories, Inc" 327 "Sonceboz SA" 326 "Akron Brass Company" 325 "ASM Automation Sensorik Messtechnik GmbH" 324 "Snap-on Diagnostics" 323 "Mobileye Vision Technologies Ltd." 322 "MICHENKA s.r.o." 321 "Ultra Electronics, Electrics" 320 "Miedema Landbouwwerktuigenfabriek B.V." 319 "Cadec Global" 318 "SAT Plan" 317 "Navtronics Bvba" 316 "ITT Flow Control" 315 "Icom Incorporated" 314 "CSM GmbH" 313 "Ilmor Engineering, Inc" 312 "Lectronix, Inc." 271 "Cole Hersee" 270 "Tennant" 269 "Saft America Inc.,  Space & Defense Division" 268 "Accurate Technologies" 267 "Red Lion Controls, Inc" 266 "International Thermal Research Ltd" 265 "MTS Sensor Technologie GmbH" 264 "Autolync" 248 "Cooper Standard Automotive Active Systems Group" 247 "ePULSE" 246 "Class 1, Inc" 245 "Capstan Ag Systems, Inc." 244 "Techno-Matic" 243 "eRide, Inc." 242 "Kokusandenki Co. Ltd" 241 "Schneider Automation SAS " 240 "Vanair Mfg" 239 "May & Scofield Ltd" 238 "ZF Friedrichshafen AG" 237 "Agtron Enterprises Inc" 236 "Norac Systems International Inc" 235 "SailorMade Marine Telemetry - Tetra Technology Ltd." 234 "Mondial electronic GmbH" ;
VAL_ 2566838526 Function 127 "Reserved" 126 "Reserved" 125 "Reserved" 124 "Reserved" 123 "Reserved" 122 "Reserved" 121 "Reserved" 120 "Reserved" 119 "Reserved" 118 "Reserved" 117 "Reserved" 116 "Reserved" 115 "Reserved" 114 "Reserved" 113 "Reserved" 112 "Reserved" 111 "Reserved" 110 "Reserved" 109 "Reserved" 108 "Reserved" 107 "Reserved" 106 "Reserved" 105 "Reserved" 104 "Reserved" 103 "Reserved" 102 "Reserved" 101 "Reserved" 42 "Water Pump Control" 41 "Lighting - Operator Controls" 40 "Seat Control" 39 "Ignition Control Module" 38 "Tire Pressure Control" 37 "Cab Controller" 36 "Pneumatic - System Controller" 35 "Suspension - System Controller" 34 "Hydraulic Pump Controller" 33 "System Monitor" 32 "Headway Controller" 31 "Propulsion Battery Charger" 30 "Management Computer" 29 "Virtual Terminal (in cab)" 28 "Off Vehicle Gateway" 27 "Power TakeOff (Secondary or Front)" 26 "Body Controller" 25 "Network Interconnect ECU" 24 "Vehicle Security" 23 "Vehicle Navigation" 22 "Aerodynamic Control" 21 "Cab Climate Control" 20 "Trip Recorder" 19 "Instrument Cluster" 18 "Suspension - Drive Axle" 17 "Suspension - Steer Axle" 16 "Steering Controller" 15 "Fuel System" 14 "Cruise Control" 13 "Retarder - Driveline" 12 "Retarder - Engine" 11 "Brakes - Drive Axle" 10 "Brakes - Steer Axle" 9 "Brakes - System Controller" 8 "Axle - Drive" 7 "Axle - Steering" 6 "Power TakeOff - (Main or Rear)" 5 "Shift Control/Console" 4 "Battery Pack Monitor" 3 "Transmission" 2 "Electric Propulsion Control" 1 "Auxiliary Power Unit (APU)" 0 "Engine" 100 "Reserved" 99 "Reserved" 98 "Reserved" 97 "Reserved" 96 "Reserved" 95 "Reserved" 94 "Reserved" 93 "Reserved" 92 "Reserved" 91 "Reserved" 90 "Reserved" 89 "Reserved" 88 "Reserved" 87 "Reserved" 86 "Reserved" 85 "Reserved" 84 "Reserved" 83 "Reserved" 82 "Reserved" 81 "Reserved" 80 "Reserved" 79 "Reserved" 78 "Reserved" 77 "Fuel Properties Sensor" 76 "Temperature Sensor" 75 "Supplemental Fan" 74 "Lubrication System" 73 "Rollover Detection Control" 72 "Coolant Valve Controller" 71 "Transfer Case Control" 70 "Auxiliary Regeneration Device" 69 "Engine Emission Aftertreatement System" 68 "Aftertreatment system gas measurement" 67 "Electrical System Controller" 66 "I/O Controller" 65 "Gas Flow Measurement" 64 "Endurance Braking" 63 "Engine Valve Controller" 62 "On-Board Diagnostic Unit" 61 "File Server/Printer" 60 "Cab Display" 59 "Starter" 58 "Fan Drive Control" 57 "Steering Column Unit" 56 "Communications Unit, Radio" 55 "Communications Unit, Satellite" 54 "Communications Unit, Cellular" 53 "Alternator/Charging System" 52 "Chassis Controller" 51 "Forward-Looking Collision Warning System" 50 "Auxiliary Heater" 49 "Clutch/Converter Control" 48 "Ramp Control" 47 "Information System Controller" 46 "Oil Sensor Unit" 45 "Vehicle Dynamic Stability Control" 44 "Exhaust Emission Control" 43 "Transmission Display" ;
VAL_ 2566838526 VehicleSystem 0 "Non-specific System" 127 "Not Available" ;
VAL_ 2566838526 VehicleSystem5 127 "Not Available" 0 "Ind. Process Control Stationary" ;
VAL_ 2566838526 VehicleSystem4 125 "Entertainment" 120 "Display" 85 "External Environment" 75 "Sensor Communication Interface" 35 "Electrical Generation" 100 "Deck, Cargo and Fishing Equipment" 90 "Internal Environment" 80 "Instrumentation/General Systems (deprecate)" 70 "Communications" 60 "Navigation" 50 "Propulsion" 40 "Steering and Control Surfaces" 30 "Electrical Distribution" 25 "Inter/Intranetwork Device" 20 "Safety Systems" 10 "System Tools" 127 "Not Available" 0 "Non-specific System" ;
VAL_ 2566838526 VehicleSystem3 8 "Grader" 7 "Four Wheel Drive Loader" 6 "Forklift" 5 "Excavator" 4 "Crawler" 3 "Backhoe" 2 "Articulated Dump Truck" 1 "Skid Steer Loader" 127 "Not Available" 0 "Non-specific System" ;
VAL_ 2566838526 VehicleSystem2 25 "Slurry Applicators" 24 "Utility Vehicles" 23 "Mulchers" 22 "Timber Processing Machines" 21 "Timber loaders" 20 "Forwarders" 19 "Timber Harvesters" 17 "Sensor Systems" 16 "Skidder" 15 "Earth Work" 14 "Special Crops" 13 "Powered Auxiliary Device" 12 "Farm Yard Operations" 11 "Transport/Trailer" 10 "Irrigation" 9 "Forage" 8 "Root Harvesters" 7 "Harvesters" 6 "Sprayers" 5 "Fertilizers" 4 "Planters/Seeders" 3 "Secondary Tillage" 2 "Tillage" 1 "Tractor" 127 "Not Available" 0 "Non-specific System" ;
VAL_ 2566838526 VehicleSystem1 2 "Trailer" 1 "Tractor" 127 "Not Available" 0 "Non-specific System" ;
VAL_ 2566838526 IndustryGroup 0 "Global" 1 "OnHighway" 2 "AgriculturalAndForestry" 3 "Construction" 4 "Marine" 5 "Reserved" 7 "NotAvailable" ;
VAL_ 2565799678 ManufacturerCode 454 "NGK Spark Plug Co. Ltd" 453 "Cooper Bussmann" 452 "WIKA Alexander Wiegand SE & Co. KG" 451 "Parker Hannifin Corp" 450 "Dycor Technologies Ltd." 449 "Polaris Industries Inc" 448 "Stanadyne Corporation, Electronics Systems" 447 "Great Plains Mfg." 446 "CertTech, L.L.C." 445 "KAT MECHATRONIC, Electronic Product Division" 444 "ITT Power Solutions" 443 "SignalQuest, Inc." 442 "Horsch Maschinen GmbH" 441 "PTG Reifendruckregelsysteme GmbH" 440 "Cummins Power Generation" 439 "Hyundai Heavy Industries" 438 "Comar Systems Ltd" 437 "Digital Yacht Limited" 436 "Kinze Manufacturing" 435 "Zunhammer GmbH" 434 "Stored Energy Systems" 433 "Rowe Electronics" 432 "S&A Systems, Inc." 431 "Tohatsu Corporation" 430 "Auteq Telematica S.A." 479 "Vapor Bus International" 478 "OceanSat BV" 477 "OilQuick AB" 476 "Hummingbird Marine Electronics" 475 "GME" 474 "Persen Technologies Inc." 473 "Boss Industries, Inc." 472 "Tenneco Inc." 471 "Sea Cross Marine AB" 470 "SI-TEX Marine Electronics" 469 "RA Consulting GmbH" 468 "Tyco Fire Protection Products" 467 "Lely Industries N.V." 466 "Veethree Electronics and Marine LLC" 465 "Ashcroft Inc" 464 "Leach International Corporation" 463 "PROBOTIQ" 462 "IHI Shibaura Machinery Corporation" 461 "HAWE Hydraulik SE" 460 "San Giorgio S.E.I.N." 459 "Alltek Marine Electronics Corp" 458 "Control Solutions, Inc." 457 "RUSELPROM-ElectricDrive Ltd" 456 "General Kinetics" 455 "ADZ NAGANO GmbH" 429 "Rota Engineering Ltd." 428 "Mfg_428" 427 "Mfg_427" 426 "Mfg_426" 425 "Methode Electronics Inc, MDI" 424 "Odyne LLC" 423 "BSM Wireless, Inc." 422 "True Heading AB" 421 "Vertex Standard Co., Ltd" 420 "Vermeer Corporation, ACS Group" 419 "Fusion Electronics Ltd" 418 "Intellistick Inc" 417 "KZValve" 416 "Kubota Corporation" 415 "Valid Manufacturing Ltd." 414 "Cattron Group International" 413 "Datapross Nijbroek bv" 412 "WebTech Wireless Inc." 411 "Hy-Drive Technologies Ltd." 410 "COBO S.p.A. Divisione 3B6" 409 "Transfluid S.r.L." 408 "Corvus Energy Ltd." 407 "Comtech Mobile Datacom" 406 "Vecima Networks Inc." 405 "Wema System AS" 404 "Com Nav Marine Ltd" 403 "Trackwell ADS, Inc." 402 "Simma Software, Inc." 401 "Torqeedo GmbH" 400 "Livorsi Marine" 399 "ISEKI & Co., Ltd." 398 "Hilite International" 397 "Sanyo-kiki Co Ltd." 396 "Beyond Measure" 395 "GENTEC S.R.L." 394 "Capi 2 Nederland BV" 393 "Harvest Tec, Inc" 392 "Tianyuan Technology Co Ltd." 391 "Electronic Design for Industry, Inc" 390 "Partech Inc." 389 "Benchmark Electronics, Minnesota Division" 388 "Innomatix, LLC" 387 "Orscheln Products, LLC" 386 "JLG Automation BVBA" 385 "Johnson Outdoor Marine Electronics" 384 "Camano Light" 383 "MCL Industries" 382 "National Agricultural and Food Research Organization" 380 "Suntech International Ltd." 379 "Yamabiko Corporation" 378 "Glendinning Marine Products" 377 "ifm electronic gmbh" 376 "Quake Global" 375 "Williams Controls Inc." 372 "Delphi" 381 "B&G" 374 "Northern Lights, Inc." 373 "Electronic Design Inc." 371 "Heinzmann GmbH & Co. KG" 370 "Rolls-Royce Marine AS" 369 "Power Torque Engineering Ltd" 368 "HANSENHOF_electronic" 367 "Fliegl Agrartechnik" 366 "Viewnyx Corp." 365 "Digi-Star, LLC" 364 "OEM Controls Inc." 363 "BEI Duncan" 362 "Alois Poettinger Maschinenfabrik GmbH" 361 "InMach" 360 "HJS Emission Technology GmbH & Co KG" 359 "Ludwig Bergmann GmbH" 358 "Victron Energy BV" 357 "Hardi International A/S" 356 "Fischer Panda Generators, Inc" 355 "Mastervolt International B.V." 354 "Junkkari OY" 353 "Hegemon Electronics, Inc." 352 "SAME DEUTZ-FAHR" 351 "Thrane & Thrane" 350 "Noris Marine Systems GmbH & Co KG" 349 "Suonentiet" 348 "Amazonen Werke H. Dreyer" 347 "Honeywell" 346 "Control Solutions" 345 "Korean Maritime University" 344 "Parvus Corporation" 343 "Baumer Group" 342 "THOMAS MAGNETE GmbH" 341 "Boning GmbH & Co" 340 "Continental AG" 339 "Competence Center ISOBUS e.V." 338 "GRAF-SYTECO" 337 "Carraro S.p.A." 336 "APE s.r.o." 335 "Evo Electric Ltd" 334 "Takata-Petri AG" 333 "Hadley Products Corporation" 332 "HWH Corporation" 331 "Horton, Inc." 330 "Kidde Aerospace and Defense" 329 "Deif A/S" 328 "Qwerty Electronik AB" 252 "Sensor-Technik Wiedemann GmbH" 251 "German Agricultural Society" 250 "Kuhn Group" 249 "Schaltbau GmbH" 233 "Yacht Monitoring Solutions Inc." 232 "TSD Integrated Controls" 1863 "Thomas G. Faria Co." 1862 "Sanshin" 1861 "Vector North America" 1860 "MMP" 1859 "Kvasar AB" 1858 "Litton" 1857 "Simrad" 1856 "Trimble" 1855 "Furuno USA" 1854 "Northstar Technologies" 1853 "Japan Radio Co." 1852 "Navionics" 1851 "Raymarine" 1850 "Teleflex" 222 "Generac Power Systems, Inc." 221 "SiE" 220 "Beede Electrical Instrument Company, Inc." 219 "Cat OEM Solutions" 218 "Gits Manufacturing Company" 217 "RM Michaelides Software & Elektronik GmbH" 216 "Paneltronics Inc." 215 "Aetna Engineering/Fireboy-Xintex" 214 "MC elettronica Srl" 213 "CNH Belgium N.V." 212 "Sure Power Industries, Inc." 211 "DNA Group" 210 "Iteris, Inc." 209 "Bell Equip. Co. SA (PTY) LTD" 208 "Drew Technologies, Inc." 207 "Otto Engineering" 206 "port GmbH" 205 "SmarTire Systems Inc" 204 "The Morey Corporation" 203 "MILtronik GmbH" 202 "Curtis Instruments, Inc." 201 "Disenos y Tecnologia S.A." 200 "MGM Brakes" 199 "Actia Corp." 198 "Mystic Valley Communications" 197 "Mechron Power Systems" 196 "LEMKEN GmbH & Co. KG" 195 "General Engine Products" 194 "TriMark Corporation" 193 "Nobletec" 192 "Floscan" 191 "XATA Corporation" 190 "Hella KGaA Hueck & Co." 189 "QUALCOMM" 188 "EMP Corp." 187 "Air-Weigh" 186 "Altronic, Inc." 185 "Beede Electrical Instrument Company" 184 "EIA Electronics" 183 "KDS Controls, Inc." 182 "Vehicle Systems Engineering B.V." 181 "Coretronics, Inc." 180 "Smart Power Systems" 179 "TeeJet Technologies Denmark" 178 "Siemens VDO Automotive AG" 177 "Diagnostic System Associates" 176 "Moritz Aerospace" 175 "Veris Technologies, Inc." 174 "AB Volvo Penta" 173 "Ryeso, Inc." 172 "Yanmar Marine USA" 171 "Wachendorff Elektronik GmbH & Co. KG" 170 "Computronics Corporation Ltd." 169 "Marlin Technologies Inc." 168 "Xantrex" 167 "JLG Industries Inc." 166 "Phoenix International" 165 "CPAC Systems AB" 164 "DaimlerChrysler Off-Highway" 163 "BRP Inc." 162 "Axiomatic Technologies" 161 "Offshore Systems (UK) Limited" 160 "Nido" 159 "NTech Industries Inc." 158 "Firestone Industrial Products Company" 157 "ISSPRO Inc." 156 "ITT Industries - Cannon" 155 "Vetronix Corporation" 154 "Westerbeke Corporation" 153 "Woodward, Industrial Controls Division" 152 "elobau GmbH & Co. KG" 151 "Raven Industries Inc. - Flow Controls Division" 150 "Fleetguard" 149 "Holset" 148 "Blue Water Data, Inc." 147 "Nautibus Electronic GmbH" 146 "Maxima Technologies" 145 "MurCal Controls" 144 "Mercury Marine" 143 "W. Gmeiner GmbH & Co." 142 "TRW Automotive (Commercial Steering Systems)" 141 "Thales Navigation Ltd." 140 "Lowrance Electronics, Inc." 139 "Caterpillar Trimble Control Technologies (CTCT), LLC" 138 "Georg Fritzmeier GmbH & Co. KG" 137 "Maretron" 136 "Komatsu Ltd." 135 "Airmar Technology Corporation" 134 "Iris Technology Ltd." 133 "Bucher Schoerling GmbH" 132 "Mulag-Fahrzeugwerk" 131 "ITT Industries" 130 "Nido - Universal Machines B.V." 129 "OMNEX Control Systems, Inc." 128 "Gerhard Duecker GmbH & Co. KG" 127 "Holland USA" 126 "Driver Tech" 125 "Nevada Automotive Test Center" 124 "Hydac Electronic" 123 "Basler Electric" 122 "FG Wilson (Engineering) Limited" 121 "HED (Hydro Electronic Devices, Inc.)" 120 "RDS Technology Ltd." 119 "IntegriNautics" 118 "Intron GmbH" 117 "HUSCO International" 116 "BEELINE Technologies" 115 "NACCO Materials Handling Group, Inc." 114 "EControls, Inc." 113 "Stress-Tek, Inc." 112 "MECALAC" 111 "Maschinenfabrik Bernard Krone GmbH" 110 "EPIQ Sensor-Nite" 109 "TeeJet Technologies Denmark" 108 "WTK-Elecktronik GmbH" 107 "Grimme Landmaschinen GmbH & Co. KG" 106 "BAE Systems Controls, Inc." 105 "Kiepe Elektrik GmbH & Co. KG" 104 "Claas Selbstfahrende Erntemaschinen GmbH" 103 "CLAAS Agrosystems GmbH & Co. KG" 102 "AGCO GmbH & Co." 101 "Sensoria" 100 "VDO Technik AG" 99 "International Transmissions Ltd (ITL)" 98 "Mueller-Elektronik GmbH & Co." 97 "Ag Leader Technology, Inc." 96 "Mech@tronic IT GmbH" 95 "Pacific Insight Electronics Corp." 94 "CNH Global N.V." 93 "Perkins Engines Company Ltd." 92 "Ag-Chem Equipment Co., Inc." 91 "BSG Bodensee Steuergeraete GmbH" 90 "Knorr-Bremse SfN GmbH" 89 "Kverneland Group, Electronics Division" 88 "Satloc Precision GPS" 87 "J.C. Bamford Excavators Ltd (JCB)" 86 "C.E. Niehoff & Company" 85 "Kohler Co." 84 "New Holland UK Limited" 83 "Eaton VORAD Technologies" 82 "Bobcat/Ingersoll-Rand" 81 "Fire Research Corp" 80 "Twin Disc, Inc." 79 "Daimler Benz AG - Engine Division (PBM)" 78 "Frank W. Murphy Manufacturing, Inc." 77 "Deere Power Systems Group" 76 "unused" 75 "Deere & Co. Agricultural Division" 74 "Eaton Axle-Brake Division" 73 "LeTourneau, Inc." 72 "Sisu Corporation" 71 "Vansco Electronics Ltd." 70 "Flex-Coil Limited" 69 "Trimble Navigation" 68 "Scania" 67 "Funk Manufacturing Company" 66 "John Deere Construction Equipment Division" 65 "MAN Nutzfahrzeuge AG" 64 "unused" 63 "ZF Industries Inc." 62 "Wabco" 61 "Volvo Truck Corp." 60 "Volvo Trucks North America Inc." 59 "VES Inc." 58 "SPX Corporation, OTC Division" 57 "Sauer-Danfoss Co." 56 "SAIC" 55 "Ryder System Inc." 54 "Meritor Wabco" 53 "Continental Automotive Systems US, Inc." 52 "Meritor Automotive, Inc." 51 "Robert Bosch GmbH" 50 "Robert Bosch Corp" 49 "RE America Inc." 48 "Pollak Alphabet" 47 "Phillips Semiconductor" 46 "Noregon Systems, Inc" 45 "PACCAR" 44 "Nippondenso Co. Ltd." 43 "International Truck and Engine Corp. Vehicle Electronics" 42 "International Truck and Engine Corp. Engine Electronics" 41 "Motorola Inc." 40 "Motorola AIEG Inc." 39 "Microfirm Inc." 38 "Micro Processor Systems Inc." 37 "Mack Trucks Inc." 36 "Lucas Ltd." 35 "Kenworth Truck Co." 34 "Kelsey Hayes Co." 33 "John Deere" 32 "Jacobs Vehicle Systems" 31 "J Pollak Corp." 30 "Isuzu Motors Ltd." 29 "Hino Motors Ltd." 28 "Grote Ind. Inc." 27 "GMC" 26 "General Motors Corp., Service Technology Group" 25 "Daimler Trucks North America LLC" 24 "Ford Motor Co., Vehicle Controls" 23 "Ford Motor Co., Heavy Truck" 22 "Ford Motor Co., Electronic Concepts $ Systems" 21 "Echilin Inc., Midland Brake Inc." 20 "Eaton Ltd" 19 "Eaton Corp. Trucking Info Services" 18 "Eaton Corp, Transmission Division" 17 "Eaton Corp. Res & Dev" 16 "Eaton Corp." 15 "Dickey-John Corp." 14 "Detroit Diesel Corporation" 13 "Delco Electronics" 12 "Deere & Company, Precision Farming" 11 "Dearborn Group Inc." 10 "Cummins Engine Co." 9 "Chrysler Corp." 8 "Caterpillar Inc." 7 "Case Corp." 6 "Berifors Electronics AB" 5 "AMP Inc." 4 "Ametek-Dixson" 3 "Ametek, US Gauge Division" 2 "Allison Transmission, GMC" 1 "Allied Signal Inc." 0 "Reserved" 231 "Topcon Positioning Systems, Inc." 230 "Saucon Technologies" 229 "Garmin International Inc." 228 "ZF Marine Electronics" 227 "Lykketronic A/S" 226 "Monaco Coach Corporation" 225 "SKF" 224 "EMMI Network, S.L." 223 "Vaueo Retarder Co., Ltd." 263 "IMMI" 262 "HydraForce, Inc" 261 "Red Dot Corporation" 260 "Reichhardt GmbH" 259 "Jetter AG" 258 "ARAG" 257 "Honda Motor Co., Ltd" 256 "Tyco Electronics AMP" 255 "MEAS France" 254 "GE Sensing" 253 "Mobile Control Systems" 298 "Holley Performance" 297 "Zonar Systems Inc" 296 "micro dynamics GmbH" 295 "BEP Marine" 294 "Grayhill Inc." 293 "Spyder Controls Corp." 292 "IKUSI - Angel Iglesias S.A." 291 "Groeneveld Transport Efficiency BV" 290 "Kuebler GmbH" 289 "Watlow" 288 "Mitsubishi FUSO Truck & Bus Corp." 287 "NTech Industries, Inc" 286 "Coelmo srl" 285 "Sea Recovery Corp" 284 "Mobile Tech Chile" 283 "CWF Hamilton & Co Ltd" 282 "Medallion Instrumentation Systems" 281 "Precision Governors LLC" 311 "Patrick Power Products" 310 "TECNORD srl" 309 "Krauss-Maffei Wegmann GmbH & Co. KG" 308 "Cyntrx" 307 "MAS Technologies" 306 "Sleipner Motor AB" 305 "NovAtel Inc" 304 "EmpirBus AB" 303 "CTS Corporation" 302 "Nissin Kogyo Co., LTD" 301 "Parker Hannifin (UK) Ltd FDE group" 300 "Systron Donner Automotive" 299 "Rauch Landmaschinen GmbH" 280 "Leica Geosystems Pty Ltd" 279 "Geometris LP" 278 "Takata Electronics" 277 "LHP Telematics" 276 "Aqua-Hot Heating Systems" 275 "Navico Egersund AS" 274 "LTW Technology Co., LTD" 273 "Active Research Limited" 272 "Gross Mechanical Laboratories, Inc" 327 "Sonceboz SA" 326 "Akron Brass Company" 325 "ASM Automation Sensorik Messtechnik GmbH" 324 "Snap-on Diagnostics" 323 "Mobileye Vision Technologies Ltd." 322 "MICHENKA s.r.o." 321 "Ultra Electronics, Electrics" 320 "Miedema Landbouwwerktuigenfabriek B.V." 319 "Cadec Global" 318 "SAT Plan" 317 "Navtronics Bvba" 316 "ITT Flow Control" 315 "Icom Incorporated" 314 "CSM GmbH" 313 "Ilmor Engineering, Inc" 312 "Lectronix, Inc." 271 "Cole Hersee" 270 "Tennant" 269 "Saft America Inc.,  Space & Defense Division" 268 "Accurate Technologies" 267 "Red Lion Controls, Inc" 266 "International Thermal Research Ltd" 265 "MTS Sensor Technologie GmbH" 264 "Autolync" 248 "Cooper Standard Automotive Active Systems Group" 247 "ePULSE" 246 "Class 1, Inc" 245 "Capstan Ag Systems, Inc." 244 "Techno-Matic" 243 "eRide, Inc." 242 "Kokusandenki Co. Ltd" 241 "Schneider Automation SAS " 240 "Vanair Mfg" 239 "May & Scofield Ltd" 238 "ZF Friedrichshafen AG" 237 "Agtron Enterprises Inc" 236 "Norac Systems International Inc" 235 "SailorMade Marine Telemetry - Tetra Technology Ltd." 234 "Mondial electronic GmbH" ;
VAL_ 2565799678 Function 127 "Reserved" 126 "Reserved" 125 "Reserved" 124 "Reserved" 123 "Reserved" 122 "Reserved" 121 "Reserved" 120 "Reserved" 119 "Reserved" 118 "Reserved" 117 "Reserved" 116 "Reserved" 115 "Reserved" 114 "Reserved" 113 "Reserved" 112 "Reserved" 111 "Reserved" 110 "Reserved" 109 "Reserved" 108 "Reserved" 107 "Reserved" 106 "Reserved" 105 "Reserved" 104 "Reserved" 103 "Reserved" 102 "Reserved" 101 "Reserved" 42 "Water Pump Control" 41 "Lighting - Operator Controls" 40 "Seat Control" 39 "Ignition Control Module" 38 "Tire Pressure Control" 37 "Cab Controller" 36 "Pneumatic - System Controller" 35 "Suspension - System Controller" 34 "Hydraulic Pump Controller" 33 "System Monitor" 32 "Headway Controller" 31 "Propulsion Battery Charger" 30 "Management Computer" 29 "Virtual Terminal (in cab)" 28 "Off Vehicle Gateway" 27 "Power TakeOff (Secondary or Front)" 26 "Body Controller" 25 "Network Interconnect ECU" 24 "Vehicle Security" 23 "Vehicle Navigation" 22 "Aerodynamic Control" 21 "Cab Climate Control" 20 "Trip Recorder" 19 "Instrument Cluster" 18 "Suspension - Drive Axle" 17 "Suspension - Steer Axle" 16 "Steering Controller" 15 "Fuel System" 14 "Cruise Control" 13 "Retarder - Driveline" 12 "Retarder - Engine" 11 "Brakes - Drive Axle" 10 "Brakes - Steer Axle" 9 "Brakes - System Controller" 8 "Axle - Drive" 7 "Axle - Steering" 6 "Power TakeOff - (Main or Rear)" 5 "Shift Control/Console" 4 "Battery Pack Monitor" 3 "Transmission" 2 "Electric Propulsion Control" 1 "Auxiliary Power Unit (APU)" 0 "Engine" 100 "Reserved" 99 "Reserved" 98 "Reserved" 97 "Reserved" 96 "Reserved" 95 "Reserved" 94 "Reserved" 93 "Reserved" 92 "Reserved" 91 "Reserved" 90 "Reserved" 89 "Reserved" 88 "Reserved" 87 "Reserved" 86 "Reserved" 85 "Reserved" 84 "Reserved" 83 "Reserved" 82 "Reserved" 81 "Reserved" 80 "Reserved" 79 "Reserved" 78 "Reserved" 77 "Fuel Properties Sensor" 76 "Temperature Sensor" 75 "Supplemental Fan" 74 "Lubrication System" 73 "Rollover Detection Control" 72 "Coolant Valve Controller" 71 "Transfer Case Control" 70 "Auxiliary Regeneration Device" 69 "Engine Emission Aftertreatement System" 68 "Aftertreatment system gas measurement" 67 "Electrical System Controller" 66 "I/O Controller" 65 "Gas Flow Measurement" 64 "Endurance Braking" 63 "Engine Valve Controller" 62 "On-Board Diagnostic Unit" 61 "File Server/Printer" 60 "Cab Display" 59 "Starter" 58 "Fan Drive Control" 57 "Steering Column Unit" 56 "Communications Unit, Radio" 55 "Communications Unit, Satellite" 54 "Communications Unit, Cellular" 53 "Alternator/Charging System" 52 "Chassis Controller" 51 "Forward-Looking Collision Warning System" 50 "Auxiliary Heater" 49 "Clutch/Converter Control" 48 "Ramp Control" 47 "Information System Controller" 46 "Oil Sensor Unit" 45 "Vehicle Dynamic Stability Control" 44 "Exhaust Emission Control" 43 "Transmission Display" ;
VAL_ 2565799678 VehicleSystem1 2 "Trailer" 1 "Tractor" 127 "Not Available" 0 "Non-specific System" ;
VAL_ 2565799678 VehicleSystem2 25 "Slurry Applicators" 24 "Utility Vehicles" 23 "Mulchers" 22 "Timber Processing Machines" 21 "Timber loaders" 20 "Forwarders" 19 "Timber Harvesters" 17 "Sensor Systems" 16 "Skidder" 15 "Earth Work" 14 "Special Crops" 13 "Powered Auxiliary Device" 12 "Farm Yard Operations" 11 "Transport/Trailer" 10 "Irrigation" 9 "Forage" 8 "Root Harvesters" 7 "Harvesters" 6 "Sprayers" 5 "Fertilizers" 4 "Planters/Seeders" 3 "Secondary Tillage" 2 "Tillage" 1 "Tractor" 127 "Not Available" 0 "Non-specific System" ;
VAL_ 2565799678 VehicleSystem3 8 "Grader" 7 "Four Wheel Drive Loader" 6 "Forklift" 5 "Excavator" 4 "Crawler" 3 "Backhoe" 2 "Articulated Dump Truck" 1 "Skid Steer Loader" 127 "Not Available" 0 "Non-specific System" ;
VAL_ 2565799678 VehicleSystem4 125 "Entertainment" 120 "Display" 85 "External Environment" 75 "Sensor Communication Interface" 35 "Electrical Generation" 100 "Deck, Cargo and Fishing Equipment" 90 "Internal Environment" 80 "Instrumentation/General Systems (deprecate)" 70 "Communications" 60 "Navigation" 50 "Propulsion" 40 "Steering and Control Surfaces" 30 "Electrical Distribution" 25 "Inter/Intranetwork Device" 20 "Safety Systems" 10 "System Tools" 127 "Not Available" 0 "Non-specific System" ;
VAL_ 2565799678 VehicleSystem5 127 "Not Available" 0 "Ind. Process Control Stationary" ;
VAL_ 2565799678 VehicleSystem 0 "Non-specific System" 127 "Not Available" ;
VAL_ 2565799678 IndustryGroup 0 "Global" 1 "On-Highway" 2 "Agricultural and Forestry" 3 "Construction" 4 "Marine" 5 "IndustrialProcessCtrlStationary" 7 "Reserved for SAE" ;
VAL_ 2565734142 ControlByte 6 "MFDB_CreateEntry" 5 "MFDB_SetMode" 4 "MFDB_Clear" 3 "MFDB_Delete" 2 "MFDB_Add" 1 "MFDB_Response" 0 "MFDB_Request" ;
VAL_ 2565734142 FilterMode 1 "PassSpecificPGNs" 0 "BlockSpecificPGNs" ;

SG_MUL_VAL_ 2559835902 CommandArbitraryAddressCapable NMControlModeIndicator 0-3, 8-8;
SG_MUL_VAL_ 2559835902 CommandVehicleSystemInstance NMControlModeIndicator 0-3, 8-8;
SG_MUL_VAL_ 2559835902 CommandIndustryGroup NMControlModeIndicator 0-3, 8-8;
SG_MUL_VAL_ 2559835902 CommandVehicleSystem NMControlModeIndicator 0-3, 8-8;
SG_MUL_VAL_ 2559835902 CommandFunction NMControlModeIndicator 0-3, 8-8;
SG_MUL_VAL_ 2559835902 CommandFunctionInstance NMControlModeIndicator 0-3, 8-8;
SG_MUL_VAL_ 2559835902 CommandECUInstance NMControlModeIndicator 0-3, 8-8;
SG_MUL_VAL_ 2559835902 CommandManufacturerCode NMControlModeIndicator 0-3, 8-8;
SG_MUL_VAL_ 2559835902 ArbitraryAddressCapableQualifier NMControlModeIndicator 0-0, 4-4, 8-8;
SG_MUL_VAL_ 2559835902 IndustryGroupQualifierFlag NMControlModeIndicator 0-0, 4-4, 8-8;
SG_MUL_VAL_ 2559835902 VehicleSystemInstanceQualifierFl NMControlModeIndicator 0-0, 4-4, 8-8;
SG_MUL_VAL_ 2559835902 VehicleSystemQualifierFlag NMControlModeIndicator 0-0, 4-4, 8-8;
SG_MUL_VAL_ 2559835902 FunctionQualifierFlag NMControlModeIndicator 0-0, 4-4, 8-8;
SG_MUL_VAL_ 2559835902 FunctionInstanceQualifierFlag NMControlModeIndicator 0-0, 4-4, 8-8;
SG_MUL_VAL_ 2559835902 ECUInstanceQualifierFlag NMControlModeIndicator 0-0, 4-4, 8-8;
SG_MUL_VAL_ 2559835902 ManufacturerCodeQualifierFlag NMControlModeIndicator 0-0, 4-4, 8-8;
SG_MUL_VAL_ 2358116094 DeleteCommandType MessageCode 5-5;
SG_MUL_VAL_ 2358116094 AddressSCCWSM MessageCode 4-4;
SG_MUL_VAL_ 2358116094 MemoryRequired MessageCode 145-145;
SG_MUL_VAL_ 2358116094 FunctionID MessageCode 50-50;
SG_MUL_VAL_ 2358116094 SCCState MessageCode 150-150;
SG_MUL_VAL_ 2358116094 RecordedFunctionID MessageCode 52-52;
SG_MUL_VAL_ 2358116094 NumberOfFaultyFunctions MessageCode 53-53;
SG_MUL_VAL_ 2358116094 SequenceNumber MessageCode 150-150;
SG_MUL_VAL_ 2358116094 StateID MessageCode 50-50;
SG_MUL_VAL_ 2358116094 IDOfFaultyClientFunction1 NumberOfFaultyFunctions 1-255;
SG_MUL_VAL_ 2358116094 NewStateID MessageCode 52-52;
SG_MUL_VAL_ 2358116094 NewFunctionExecutionState MessageCode 52-52;
SG_MUL_VAL_ 2358116094 FunctionExecutionState MessageCode 50-50;
SG_MUL_VAL_ 2358116094 SequenceState MessageCode 150-150;
SG_MUL_VAL_ 2358116094 ClientAbortError MessageCode 49-49;
SG_MUL_VAL_ 2358116094 ClientFunctionErrorStatuts1 NumberOfFaultyFunctions 1-255;
SG_MUL_VAL_ 2358116094 ClientExecutionError MessageCode 52-52;
SG_MUL_VAL_ 2358116094 TAN MessageCode 50-50;
SG_MUL_VAL_ 2358116094 OperatorConfirmationRequired1 NumberOfFaultyFunctions 1-255;
SG_MUL_VAL_ 2358116094 ClientFunctonErrorState MessageCode 150-150;
SG_MUL_VAL_ 2358116094 IDOfFaultyClientFunction2 NumberOfFaultyFunctions 2-255;
SG_MUL_VAL_ 2358116094 FunctionValue FunctionExecutionState 0-0, 2-2;
SG_MUL_VAL_ 2358116094 ReceivedTAN MessageCode 52-52;
SG_MUL_VAL_ 2358116094 ClientFunctionErrorStatuts2 NumberOfFaultyFunctions 2-255;
SG_MUL_VAL_ 2358116094 OperatorConfirmationRequired2 NumberOfFaultyFunctions 2-255;
SG_MUL_VAL_ 2358116094 IDOfFaultyClientFunction3 NumberOfFaultyFunctions 3-255;
SG_MUL_VAL_ 2358116094 ClientFunctionErrorStatuts3 NumberOfFaultyFunctions 3-255;
SG_MUL_VAL_ 2358116094 OperatorConfirmationRequired3 NumberOfFaultyFunctions 3-255;
SG_MUL_VAL_ 2358181630 LoadResponseError MessageCode 7-7;
SG_MUL_VAL_ 2358181630 StoreCommandError MessageCode 6-6;
SG_MUL_VAL_ 2358181630 DeleteCommandResponseError MessageCode 5-5;
SG_MUL_VAL_ 2358181630 CommandedSCCState MessageCode 48-48;
SG_MUL_VAL_ 2358181630 SCVersion MessageCode 144-144;
SG_MUL_VAL_ 2358181630 FunctionID MessageCode 50-50;
SG_MUL_VAL_ 2358181630 SCMState MessageCode 149-149;
SG_MUL_VAL_ 2358181630 ActivationResponseError MessageCode 4-4;
SG_MUL_VAL_ 2358181630 TransferResponseError MessageCode 3-3;
SG_MUL_VAL_ 2358181630 ConfigLabelResponseError MessageCode 2-2;
SG_MUL_VAL_ 2358181630 VersionResponseError MessageCode 1-1;
SG_MUL_VAL_ 2358181630 MemoryStatus MessageCode 145-145;
SG_MUL_VAL_ 2358181630 RecordedFunctionID MessageCode 51-51, 52-52;
SG_MUL_VAL_ 2358181630 ObjectIdOfFirstFaultyObject MessageCode 4-4;
SG_MUL_VAL_ 2358181630 SequenceNumber MessageCode 149-149;
SG_MUL_VAL_ 2358181630 RecordedStateID MessageCode 51-51;
SG_MUL_VAL_ 2358181630 GraphicsWidth MessageCode 144-144;
SG_MUL_VAL_ 2358181630 ActualVersionLabel VersionResponseError 0-0;
SG_MUL_VAL_ 2358181630 ActualConfigurationLabel ConfigLabelResponseError 0-0;
SG_MUL_VAL_ 2358181630 StateID MessageCode 50-50, 52-52;
SG_MUL_VAL_ 2358181630 FunctionExecutionStateAck MessageCode 52-52;
SG_MUL_VAL_ 2358181630 FunctionExecutionState MessageCode 50-50;
SG_MUL_VAL_ 2358181630 GraphicsHeight MessageCode 144-144;
SG_MUL_VAL_ 2358181630 ReasonIndicator MessageCode 48-48;
SG_MUL_VAL_ 2358181630 SequenceState MessageCode 149-149;
SG_MUL_VAL_ 2358181630 TAN MessageCode 51-51, 52-52;
SG_MUL_VAL_ 2358181630 ExecutionIndicationResponseError MessageCode 50-50;
SG_MUL_VAL_ 2358181630 BusyFlagMemoryAccess MessageCode 149-149;
SG_MUL_VAL_ 2358181630 RecordedFunctionValue MessageCode 51-51;
SG_MUL_VAL_ 2358181630 ReceivedTAN MessageCode 50-50;
SG_MUL_VAL_ 2358181630 BusyFlagParsing MessageCode 149-149;
SG_MUL_VAL_ 2358181630 MaxDesignatorStringLength MessageCode 144-144;
SG_MUL_VAL_ 2566730494 DiagnosticOptions FirstListedFuncCharacteristic 23-24;
SG_MUL_VAL_ 2566730494 StopAllImplementOperationsOption FirstListedFuncCharacteristic 21-22;
SG_MUL_VAL_ 2566730494 SequenceControlFuncOptions FirstListedFuncCharacteristic 19-20;
SG_MUL_VAL_ 2566730494 AdvanceTECU_MotionInitiationOpti FirstListedFuncCharacteristic 15-16;
SG_MUL_VAL_ 2566730494 AdvanceTECU_PowertrainOption FirstListedFuncCharacteristic 15-16;
SG_MUL_VAL_ 2566730494 AdvanceTECU_GuidanceOption FirstListedFuncCharacteristic 15-16;
SG_MUL_VAL_ 2566730494 AdvanceTECU_FrontHitchOption FirstListedFuncCharacteristic 15-16;
SG_MUL_VAL_ 2566730494 AdvanceTECU_NavigationOption FirstListedFuncCharacteristic 15-16;
SG_MUL_VAL_ 2566730494 AdvanceTECU_FullLightingMsgSet FirstListedFuncCharacteristic 15-16;
SG_MUL_VAL_ 2566730494 AdvanceTECU_Class3NoOptions FirstListedFuncCharacteristic 15-16;
SG_MUL_VAL_ 2566730494 BasicTECU_GuidanceOption FirstListedFuncCharacteristic 13-14;
SG_MUL_VAL_ 2566730494 BasicTECU_FrontHitchOption FirstListedFuncCharacteristic 13-14;
SG_MUL_VAL_ 2566730494 BasicTECU_NavigationOption FirstListedFuncCharacteristic 13-14;
SG_MUL_VAL_ 2566730494 BasicTECU_ClassRequiredLighting FirstListedFuncCharacteristic 13-14;
SG_MUL_VAL_ 2566730494 BasicTECU_Class2NoOptions FirstListedFuncCharacteristic 13-14;
SG_MUL_VAL_ 2566730494 BasicTECU_Class1NoOptions FirstListedFuncCharacteristic 13-14;
SG_MUL_VAL_ 2566730494 TCSectionNumberOfSections FirstListedFuncCharacteristic 11-12;
SG_MUL_VAL_ 2566730494 TCSectionNumberOfBooms FirstListedFuncCharacteristic 11-12;
SG_MUL_VAL_ 2566730494 TCGeoFuncOptions FirstListedFuncCharacteristic 9-10;
SG_MUL_VAL_ 2566730494 TCGeoSupportedChannels FirstListedFuncCharacteristic 9-10;
SG_MUL_VAL_ 2566730494 TCBasicFuncOptions FirstListedFuncCharacteristic 7-8;
SG_MUL_VAL_ 2566730494 AuxType2_SupportFunc14 FirstListedFuncCharacteristic 5-6;
SG_MUL_VAL_ 2566730494 AuxType2_SupportFunc13 FirstListedFuncCharacteristic 5-6;
SG_MUL_VAL_ 2566730494 AuxType2_SupportFunc12 FirstListedFuncCharacteristic 5-6;
SG_MUL_VAL_ 2566730494 AuxType2_SupportFunc11 FirstListedFuncCharacteristic 5-6;
SG_MUL_VAL_ 2566730494 AuxType2_SupportFunc10 FirstListedFuncCharacteristic 5-6;
SG_MUL_VAL_ 2566730494 AuxType2_SupportFunc09 FirstListedFuncCharacteristic 5-6;
SG_MUL_VAL_ 2566730494 AuxType2_SupportFunc08 FirstListedFuncCharacteristic 5-6;
SG_MUL_VAL_ 2566730494 AuxType2_SupportFunc07 FirstListedFuncCharacteristic 5-6;
SG_MUL_VAL_ 2566730494 AuxType2_SupportFunc06 FirstListedFuncCharacteristic 5-6;
SG_MUL_VAL_ 2566730494 AuxType2_SupportFunc05 FirstListedFuncCharacteristic 5-6;
SG_MUL_VAL_ 2566730494 AuxType2_SupportFunc04 FirstListedFuncCharacteristic 5-6;
SG_MUL_VAL_ 2566730494 AuxType2_SupportFunc03 FirstListedFuncCharacteristic 5-6;
SG_MUL_VAL_ 2566730494 AuxType2_SupportFunc02 FirstListedFuncCharacteristic 5-6;
SG_MUL_VAL_ 2566730494 AuxType2_SupportFunc01 FirstListedFuncCharacteristic 5-6;
SG_MUL_VAL_ 2566730494 AuxType2_SupportFunc00 FirstListedFuncCharacteristic 5-6;
SG_MUL_VAL_ 2566730494 AuxType1_SupportFunc2 FirstListedFuncCharacteristic 3-4;
SG_MUL_VAL_ 2566730494 AuxType1_SupportFunc1 FirstListedFuncCharacteristic 3-4;
SG_MUL_VAL_ 2566730494 AuxType1_SupportFunc0 FirstListedFuncCharacteristic 3-4;
SG_MUL_VAL_ 2566730494 VTFuncOptions FirstListedFuncCharacteristic 1-2;
SG_MUL_VAL_ 2565799678 VehicleSystem1 IndustryGroup 1-1;
SG_MUL_VAL_ 2565799678 VehicleSystem2 IndustryGroup 2-2;
SG_MUL_VAL_ 2565799678 VehicleSystem3 IndustryGroup 3-3;
SG_MUL_VAL_ 2565799678 VehicleSystem4 IndustryGroup 4-4;
SG_MUL_VAL_ 2565799678 VehicleSystem5 IndustryGroup 5-5;
SG_MUL_VAL_ 2565799678 VehicleSystem IndustryGroup 0-0;
SG_MUL_VAL_ 2565799678 VehicleSystem1 IndustryGroup 1-1;
SG_MUL_VAL_ 2565799678 VehicleSystem2 IndustryGroup 2-2;
SG_MUL_VAL_ 2565799678 VehicleSystem3 IndustryGroup 3-3;
SG_MUL_VAL_ 2565799678 VehicleSystem4 IndustryGroup 4-4;
SG_MUL_VAL_ 2565799678 VehicleSystem5 IndustryGroup 5-5;
SG_MUL_VAL_ 2565799678 VehicleSystem IndustryGroup 0-0;
